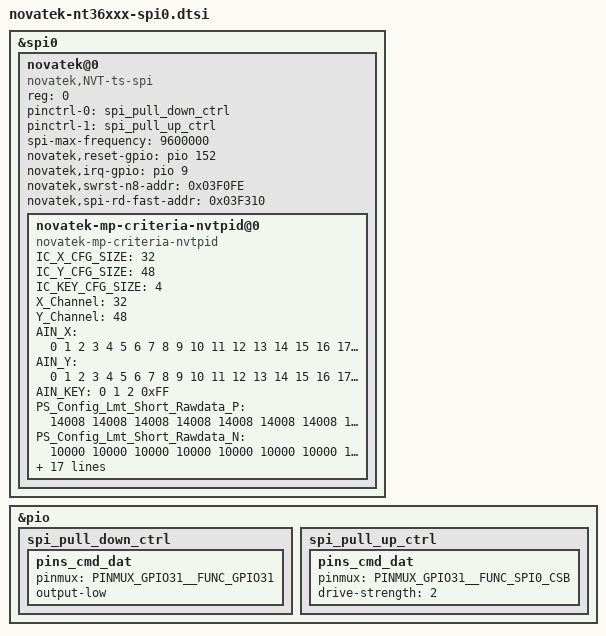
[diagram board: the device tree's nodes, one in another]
// SPDX-License-Identifier: GPL-2.0
/*
 * Copyright (c) 2022 MediaTek Inc.
 *
 */

&spi0 {
	status = "okay";
	#address-cells = <1>;
	#size-cells = <0>;
	/* Novatek device tree node */
	novatek@0 {
		compatible = "novatek,NVT-ts-spi";
		reg = <0>; //Same as CS ID
		status = "okay";
		pinctrl-names = "spi_pull_down", "spi_pull_up";
                pinctrl-0 = <&spi_pull_down_ctrl>;
                pinctrl-1 = <&spi_pull_up_ctrl>;
		//4800000,9600000,15000000,19200000
		spi-max-frequency = <9600000>;
		novatek,reset-gpio = <&pio 152 0x00>;
		novatek,irq-gpio = <&pio 9 0x00>;
		/* 525 */
		//novatek,swrst-n8-addr = <0x01F01A>;
		/* 672A, 525B, 675, 526, 672C, 523 */
		novatek,swrst-n8-addr = <0x03F0FE>;
		novatek,spi-rd-fast-addr = <0x03F310>;
		/* MP */
		//novatek,mp-support-dt;
		
		
		novatek-mp-criteria-nvtpid@0 {
			#address-cells = <1>;
			#size-cells = <0>;
			compatible = "novatek-mp-criteria-nvtpid";

			/* MP Config */
			IC_X_CFG_SIZE = <32>;
			IC_Y_CFG_SIZE = <48>;
			IC_KEY_CFG_SIZE = <4>;
			X_Channel = <32>;
			Y_Channel = <48>;
			AIN_X = <0 1 2 3 4 5 6 7 8 9 10 11 12 13 14 15 16 17 18 19 20 21 22 23 24 25 26 27 28 29 30 31>;
			AIN_Y = <0 1 2 3 4 5 6 7 8 9 10 11 12 13 14 15 16 17 18 19 20 21 22 23 24 25 26 27 28 29 30 31 32 33 34 35 36 37 38 39 40 41 42 43 44 45 46 47>;
			AIN_KEY = <0 1 2 0xFF>;

			/* MP Criteria */
			PS_Config_Lmt_Short_Rawdata_P = <
				14008 14008 14008 14008 14008 14008 14008 14008 14008 14008 14008 14008 14008 14008 14008 14008 14008 14008 14008 14008 14008 14008 14008 14008 14008 14008 14008 14008 14008 14008 14008 14008
				14008 14008 14008 14008 14008 14008 14008 14008 14008 14008 14008 14008 14008 14008 14008 14008 14008 14008 14008 14008 14008 14008 14008 14008 14008 14008 14008 14008 14008 14008 14008 14008
				14008 14008 14008 14008 14008 14008 14008 14008 14008 14008 14008 14008 14008 14008 14008 14008 14008 14008 14008 14008 14008 14008 14008 14008 14008 14008 14008 14008 14008 14008 14008 14008
				14008 14008 14008 14008 14008 14008 14008 14008 14008 14008 14008 14008 14008 14008 14008 14008 14008 14008 14008 14008 14008 14008 14008 14008 14008 14008 14008 14008 14008 14008 14008 14008
				14008 14008 14008 14008 14008 14008 14008 14008 14008 14008 14008 14008 14008 14008 14008 14008 14008 14008 14008 14008 14008 14008 14008 14008 14008 14008 14008 14008 14008 14008 14008 14008
				14008 14008 14008 14008 14008 14008 14008 14008 14008 14008 14008 14008 14008 14008 14008 14008 14008 14008 14008 14008 14008 14008 14008 14008 14008 14008 14008 14008 14008 14008 14008 14008
				14008 14008 14008 14008 14008 14008 14008 14008 14008 14008 14008 14008 14008 14008 14008 14008 14008 14008 14008 14008 14008 14008 14008 14008 14008 14008 14008 14008 14008 14008 14008 14008
				14008 14008 14008 14008 14008 14008 14008 14008 14008 14008 14008 14008 14008 14008 14008 14008 14008 14008 14008 14008 14008 14008 14008 14008 14008 14008 14008 14008 14008 14008 14008 14008
				14008 14008 14008 14008 14008 14008 14008 14008 14008 14008 14008 14008 14008 14008 14008 14008 14008 14008 14008 14008 14008 14008 14008 14008 14008 14008 14008 14008 14008 14008 14008 14008
				14008 14008 14008 14008 14008 14008 14008 14008 14008 14008 14008 14008 14008 14008 14008 14008 14008 14008 14008 14008 14008 14008 14008 14008 14008 14008 14008 14008 14008 14008 14008 14008
				14008 14008 14008 14008 14008 14008 14008 14008 14008 14008 14008 14008 14008 14008 14008 14008 14008 14008 14008 14008 14008 14008 14008 14008 14008 14008 14008 14008 14008 14008 14008 14008
				14008 14008 14008 14008 14008 14008 14008 14008 14008 14008 14008 14008 14008 14008 14008 14008 14008 14008 14008 14008 14008 14008 14008 14008 14008 14008 14008 14008 14008 14008 14008 14008
				14008 14008 14008 14008 14008 14008 14008 14008 14008 14008 14008 14008 14008 14008 14008 14008 14008 14008 14008 14008 14008 14008 14008 14008 14008 14008 14008 14008 14008 14008 14008 14008
				14008 14008 14008 14008 14008 14008 14008 14008 14008 14008 14008 14008 14008 14008 14008 14008 14008 14008 14008 14008 14008 14008 14008 14008 14008 14008 14008 14008 14008 14008 14008 14008
				14008 14008 14008 14008 14008 14008 14008 14008 14008 14008 14008 14008 14008 14008 14008 14008 14008 14008 14008 14008 14008 14008 14008 14008 14008 14008 14008 14008 14008 14008 14008 14008
				14008 14008 14008 14008 14008 14008 14008 14008 14008 14008 14008 14008 14008 14008 14008 14008 14008 14008 14008 14008 14008 14008 14008 14008 14008 14008 14008 14008 14008 14008 14008 14008
				14008 14008 14008 14008 14008 14008 14008 14008 14008 14008 14008 14008 14008 14008 14008 14008 14008 14008 14008 14008 14008 14008 14008 14008 14008 14008 14008 14008 14008 14008 14008 14008
				14008 14008 14008 14008 14008 14008 14008 14008 14008 14008 14008 14008 14008 14008 14008 14008 14008 14008 14008 14008 14008 14008 14008 14008 14008 14008 14008 14008 14008 14008 14008 14008
				14008 14008 14008 14008 14008 14008 14008 14008 14008 14008 14008 14008 14008 14008 14008 14008 14008 14008 14008 14008 14008 14008 14008 14008 14008 14008 14008 14008 14008 14008 14008 14008
				14008 14008 14008 14008 14008 14008 14008 14008 14008 14008 14008 14008 14008 14008 14008 14008 14008 14008 14008 14008 14008 14008 14008 14008 14008 14008 14008 14008 14008 14008 14008 14008
				14008 14008 14008 14008 14008 14008 14008 14008 14008 14008 14008 14008 14008 14008 14008 14008 14008 14008 14008 14008 14008 14008 14008 14008 14008 14008 14008 14008 14008 14008 14008 14008
				14008 14008 14008 14008 14008 14008 14008 14008 14008 14008 14008 14008 14008 14008 14008 14008 14008 14008 14008 14008 14008 14008 14008 14008 14008 14008 14008 14008 14008 14008 14008 14008
				14008 14008 14008 14008 14008 14008 14008 14008 14008 14008 14008 14008 14008 14008 14008 14008 14008 14008 14008 14008 14008 14008 14008 14008 14008 14008 14008 14008 14008 14008 14008 14008
				14008 14008 14008 14008 14008 14008 14008 14008 14008 14008 14008 14008 14008 14008 14008 14008 14008 14008 14008 14008 14008 14008 14008 14008 14008 14008 14008 14008 14008 14008 14008 14008
				14008 14008 14008 14008 14008 14008 14008 14008 14008 14008 14008 14008 14008 14008 14008 14008 14008 14008 14008 14008 14008 14008 14008 14008 14008 14008 14008 14008 14008 14008 14008 14008
				14008 14008 14008 14008 14008 14008 14008 14008 14008 14008 14008 14008 14008 14008 14008 14008 14008 14008 14008 14008 14008 14008 14008 14008 14008 14008 14008 14008 14008 14008 14008 14008
				14008 14008 14008 14008 14008 14008 14008 14008 14008 14008 14008 14008 14008 14008 14008 14008 14008 14008 14008 14008 14008 14008 14008 14008 14008 14008 14008 14008 14008 14008 14008 14008
				14008 14008 14008 14008 14008 14008 14008 14008 14008 14008 14008 14008 14008 14008 14008 14008 14008 14008 14008 14008 14008 14008 14008 14008 14008 14008 14008 14008 14008 14008 14008 14008
				14008 14008 14008 14008 14008 14008 14008 14008 14008 14008 14008 14008 14008 14008 14008 14008 14008 14008 14008 14008 14008 14008 14008 14008 14008 14008 14008 14008 14008 14008 14008 14008
				14008 14008 14008 14008 14008 14008 14008 14008 14008 14008 14008 14008 14008 14008 14008 14008 14008 14008 14008 14008 14008 14008 14008 14008 14008 14008 14008 14008 14008 14008 14008 14008
				14008 14008 14008 14008 14008 14008 14008 14008 14008 14008 14008 14008 14008 14008 14008 14008 14008 14008 14008 14008 14008 14008 14008 14008 14008 14008 14008 14008 14008 14008 14008 14008
				14008 14008 14008 14008 14008 14008 14008 14008 14008 14008 14008 14008 14008 14008 14008 14008 14008 14008 14008 14008 14008 14008 14008 14008 14008 14008 14008 14008 14008 14008 14008 14008
				14008 14008 14008 14008 14008 14008 14008 14008 14008 14008 14008 14008 14008 14008 14008 14008 14008 14008 14008 14008 14008 14008 14008 14008 14008 14008 14008 14008 14008 14008 14008 14008
				14008 14008 14008 14008 14008 14008 14008 14008 14008 14008 14008 14008 14008 14008 14008 14008 14008 14008 14008 14008 14008 14008 14008 14008 14008 14008 14008 14008 14008 14008 14008 14008
				14008 14008 14008 14008 14008 14008 14008 14008 14008 14008 14008 14008 14008 14008 14008 14008 14008 14008 14008 14008 14008 14008 14008 14008 14008 14008 14008 14008 14008 14008 14008 14008
				14008 14008 14008 14008 14008 14008 14008 14008 14008 14008 14008 14008 14008 14008 14008 14008 14008 14008 14008 14008 14008 14008 14008 14008 14008 14008 14008 14008 14008 14008 14008 14008
				14008 14008 14008 14008 14008 14008 14008 14008 14008 14008 14008 14008 14008 14008 14008 14008 14008 14008 14008 14008 14008 14008 14008 14008 14008 14008 14008 14008 14008 14008 14008 14008
				14008 14008 14008 14008 14008 14008 14008 14008 14008 14008 14008 14008 14008 14008 14008 14008 14008 14008 14008 14008 14008 14008 14008 14008 14008 14008 14008 14008 14008 14008 14008 14008
				14008 14008 14008 14008 14008 14008 14008 14008 14008 14008 14008 14008 14008 14008 14008 14008 14008 14008 14008 14008 14008 14008 14008 14008 14008 14008 14008 14008 14008 14008 14008 14008
				14008 14008 14008 14008 14008 14008 14008 14008 14008 14008 14008 14008 14008 14008 14008 14008 14008 14008 14008 14008 14008 14008 14008 14008 14008 14008 14008 14008 14008 14008 14008 14008
				14008 14008 14008 14008 14008 14008 14008 14008 14008 14008 14008 14008 14008 14008 14008 14008 14008 14008 14008 14008 14008 14008 14008 14008 14008 14008 14008 14008 14008 14008 14008 14008
				14008 14008 14008 14008 14008 14008 14008 14008 14008 14008 14008 14008 14008 14008 14008 14008 14008 14008 14008 14008 14008 14008 14008 14008 14008 14008 14008 14008 14008 14008 14008 14008
				14008 14008 14008 14008 14008 14008 14008 14008 14008 14008 14008 14008 14008 14008 14008 14008 14008 14008 14008 14008 14008 14008 14008 14008 14008 14008 14008 14008 14008 14008 14008 14008
				14008 14008 14008 14008 14008 14008 14008 14008 14008 14008 14008 14008 14008 14008 14008 14008 14008 14008 14008 14008 14008 14008 14008 14008 14008 14008 14008 14008 14008 14008 14008 14008
				14008 14008 14008 14008 14008 14008 14008 14008 14008 14008 14008 14008 14008 14008 14008 14008 14008 14008 14008 14008 14008 14008 14008 14008 14008 14008 14008 14008 14008 14008 14008 14008
				14008 14008 14008 14008 14008 14008 14008 14008 14008 14008 14008 14008 14008 14008 14008 14008 14008 14008 14008 14008 14008 14008 14008 14008 14008 14008 14008 14008 14008 14008 14008 14008
				14008 14008 14008 14008 14008 14008 14008 14008 14008 14008 14008 14008 14008 14008 14008 14008 14008 14008 14008 14008 14008 14008 14008 14008 14008 14008 14008 14008 14008 14008 14008 14008
				14008 14008 14008 14008 14008 14008 14008 14008 14008 14008 14008 14008 14008 14008 14008 14008 14008 14008 14008 14008 14008 14008 14008 14008 14008 14008 14008 14008 14008 14008 14008 14008
				14008 14008 14008>;

			PS_Config_Lmt_Short_Rawdata_N = <
				10000 10000 10000 10000 10000 10000 10000 10000 10000 10000 10000 10000 10000 10000 10000 10000 10000 10000 10000 10000 10000 10000 10000 10000 10000 10000 10000 10000 10000 10000 10000 10000
				10000 10000 10000 10000 10000 10000 10000 10000 10000 10000 10000 10000 10000 10000 10000 10000 10000 10000 10000 10000 10000 10000 10000 10000 10000 10000 10000 10000 10000 10000 10000 10000
				10000 10000 10000 10000 10000 10000 10000 10000 10000 10000 10000 10000 10000 10000 10000 10000 10000 10000 10000 10000 10000 10000 10000 10000 10000 10000 10000 10000 10000 10000 10000 10000
				10000 10000 10000 10000 10000 10000 10000 10000 10000 10000 10000 10000 10000 10000 10000 10000 10000 10000 10000 10000 10000 10000 10000 10000 10000 10000 10000 10000 10000 10000 10000 10000
				10000 10000 10000 10000 10000 10000 10000 10000 10000 10000 10000 10000 10000 10000 10000 10000 10000 10000 10000 10000 10000 10000 10000 10000 10000 10000 10000 10000 10000 10000 10000 10000
				10000 10000 10000 10000 10000 10000 10000 10000 10000 10000 10000 10000 10000 10000 10000 10000 10000 10000 10000 10000 10000 10000 10000 10000 10000 10000 10000 10000 10000 10000 10000 10000
				10000 10000 10000 10000 10000 10000 10000 10000 10000 10000 10000 10000 10000 10000 10000 10000 10000 10000 10000 10000 10000 10000 10000 10000 10000 10000 10000 10000 10000 10000 10000 10000
				10000 10000 10000 10000 10000 10000 10000 10000 10000 10000 10000 10000 10000 10000 10000 10000 10000 10000 10000 10000 10000 10000 10000 10000 10000 10000 10000 10000 10000 10000 10000 10000
				10000 10000 10000 10000 10000 10000 10000 10000 10000 10000 10000 10000 10000 10000 10000 10000 10000 10000 10000 10000 10000 10000 10000 10000 10000 10000 10000 10000 10000 10000 10000 10000
				10000 10000 10000 10000 10000 10000 10000 10000 10000 10000 10000 10000 10000 10000 10000 10000 10000 10000 10000 10000 10000 10000 10000 10000 10000 10000 10000 10000 10000 10000 10000 10000
				10000 10000 10000 10000 10000 10000 10000 10000 10000 10000 10000 10000 10000 10000 10000 10000 10000 10000 10000 10000 10000 10000 10000 10000 10000 10000 10000 10000 10000 10000 10000 10000
				10000 10000 10000 10000 10000 10000 10000 10000 10000 10000 10000 10000 10000 10000 10000 10000 10000 10000 10000 10000 10000 10000 10000 10000 10000 10000 10000 10000 10000 10000 10000 10000
				10000 10000 10000 10000 10000 10000 10000 10000 10000 10000 10000 10000 10000 10000 10000 10000 10000 10000 10000 10000 10000 10000 10000 10000 10000 10000 10000 10000 10000 10000 10000 10000
				10000 10000 10000 10000 10000 10000 10000 10000 10000 10000 10000 10000 10000 10000 10000 10000 10000 10000 10000 10000 10000 10000 10000 10000 10000 10000 10000 10000 10000 10000 10000 10000
				10000 10000 10000 10000 10000 10000 10000 10000 10000 10000 10000 10000 10000 10000 10000 10000 10000 10000 10000 10000 10000 10000 10000 10000 10000 10000 10000 10000 10000 10000 10000 10000
				10000 10000 10000 10000 10000 10000 10000 10000 10000 10000 10000 10000 10000 10000 10000 10000 10000 10000 10000 10000 10000 10000 10000 10000 10000 10000 10000 10000 10000 10000 10000 10000
				10000 10000 10000 10000 10000 10000 10000 10000 10000 10000 10000 10000 10000 10000 10000 10000 10000 10000 10000 10000 10000 10000 10000 10000 10000 10000 10000 10000 10000 10000 10000 10000
				10000 10000 10000 10000 10000 10000 10000 10000 10000 10000 10000 10000 10000 10000 10000 10000 10000 10000 10000 10000 10000 10000 10000 10000 10000 10000 10000 10000 10000 10000 10000 10000
				10000 10000 10000 10000 10000 10000 10000 10000 10000 10000 10000 10000 10000 10000 10000 10000 10000 10000 10000 10000 10000 10000 10000 10000 10000 10000 10000 10000 10000 10000 10000 10000
				10000 10000 10000 10000 10000 10000 10000 10000 10000 10000 10000 10000 10000 10000 10000 10000 10000 10000 10000 10000 10000 10000 10000 10000 10000 10000 10000 10000 10000 10000 10000 10000
				10000 10000 10000 10000 10000 10000 10000 10000 10000 10000 10000 10000 10000 10000 10000 10000 10000 10000 10000 10000 10000 10000 10000 10000 10000 10000 10000 10000 10000 10000 10000 10000
				10000 10000 10000 10000 10000 10000 10000 10000 10000 10000 10000 10000 10000 10000 10000 10000 10000 10000 10000 10000 10000 10000 10000 10000 10000 10000 10000 10000 10000 10000 10000 10000
				10000 10000 10000 10000 10000 10000 10000 10000 10000 10000 10000 10000 10000 10000 10000 10000 10000 10000 10000 10000 10000 10000 10000 10000 10000 10000 10000 10000 10000 10000 10000 10000
				10000 10000 10000 10000 10000 10000 10000 10000 10000 10000 10000 10000 10000 10000 10000 10000 10000 10000 10000 10000 10000 10000 10000 10000 10000 10000 10000 10000 10000 10000 10000 10000
				10000 10000 10000 10000 10000 10000 10000 10000 10000 10000 10000 10000 10000 10000 10000 10000 10000 10000 10000 10000 10000 10000 10000 10000 10000 10000 10000 10000 10000 10000 10000 10000
				10000 10000 10000 10000 10000 10000 10000 10000 10000 10000 10000 10000 10000 10000 10000 10000 10000 10000 10000 10000 10000 10000 10000 10000 10000 10000 10000 10000 10000 10000 10000 10000
				10000 10000 10000 10000 10000 10000 10000 10000 10000 10000 10000 10000 10000 10000 10000 10000 10000 10000 10000 10000 10000 10000 10000 10000 10000 10000 10000 10000 10000 10000 10000 10000
				10000 10000 10000 10000 10000 10000 10000 10000 10000 10000 10000 10000 10000 10000 10000 10000 10000 10000 10000 10000 10000 10000 10000 10000 10000 10000 10000 10000 10000 10000 10000 10000
				10000 10000 10000 10000 10000 10000 10000 10000 10000 10000 10000 10000 10000 10000 10000 10000 10000 10000 10000 10000 10000 10000 10000 10000 10000 10000 10000 10000 10000 10000 10000 10000
				10000 10000 10000 10000 10000 10000 10000 10000 10000 10000 10000 10000 10000 10000 10000 10000 10000 10000 10000 10000 10000 10000 10000 10000 10000 10000 10000 10000 10000 10000 10000 10000
				10000 10000 10000 10000 10000 10000 10000 10000 10000 10000 10000 10000 10000 10000 10000 10000 10000 10000 10000 10000 10000 10000 10000 10000 10000 10000 10000 10000 10000 10000 10000 10000
				10000 10000 10000 10000 10000 10000 10000 10000 10000 10000 10000 10000 10000 10000 10000 10000 10000 10000 10000 10000 10000 10000 10000 10000 10000 10000 10000 10000 10000 10000 10000 10000
				10000 10000 10000 10000 10000 10000 10000 10000 10000 10000 10000 10000 10000 10000 10000 10000 10000 10000 10000 10000 10000 10000 10000 10000 10000 10000 10000 10000 10000 10000 10000 10000
				10000 10000 10000 10000 10000 10000 10000 10000 10000 10000 10000 10000 10000 10000 10000 10000 10000 10000 10000 10000 10000 10000 10000 10000 10000 10000 10000 10000 10000 10000 10000 10000
				10000 10000 10000 10000 10000 10000 10000 10000 10000 10000 10000 10000 10000 10000 10000 10000 10000 10000 10000 10000 10000 10000 10000 10000 10000 10000 10000 10000 10000 10000 10000 10000
				10000 10000 10000 10000 10000 10000 10000 10000 10000 10000 10000 10000 10000 10000 10000 10000 10000 10000 10000 10000 10000 10000 10000 10000 10000 10000 10000 10000 10000 10000 10000 10000
				10000 10000 10000 10000 10000 10000 10000 10000 10000 10000 10000 10000 10000 10000 10000 10000 10000 10000 10000 10000 10000 10000 10000 10000 10000 10000 10000 10000 10000 10000 10000 10000
				10000 10000 10000 10000 10000 10000 10000 10000 10000 10000 10000 10000 10000 10000 10000 10000 10000 10000 10000 10000 10000 10000 10000 10000 10000 10000 10000 10000 10000 10000 10000 10000
				10000 10000 10000 10000 10000 10000 10000 10000 10000 10000 10000 10000 10000 10000 10000 10000 10000 10000 10000 10000 10000 10000 10000 10000 10000 10000 10000 10000 10000 10000 10000 10000
				10000 10000 10000 10000 10000 10000 10000 10000 10000 10000 10000 10000 10000 10000 10000 10000 10000 10000 10000 10000 10000 10000 10000 10000 10000 10000 10000 10000 10000 10000 10000 10000
				10000 10000 10000 10000 10000 10000 10000 10000 10000 10000 10000 10000 10000 10000 10000 10000 10000 10000 10000 10000 10000 10000 10000 10000 10000 10000 10000 10000 10000 10000 10000 10000
				10000 10000 10000 10000 10000 10000 10000 10000 10000 10000 10000 10000 10000 10000 10000 10000 10000 10000 10000 10000 10000 10000 10000 10000 10000 10000 10000 10000 10000 10000 10000 10000
				10000 10000 10000 10000 10000 10000 10000 10000 10000 10000 10000 10000 10000 10000 10000 10000 10000 10000 10000 10000 10000 10000 10000 10000 10000 10000 10000 10000 10000 10000 10000 10000
				10000 10000 10000 10000 10000 10000 10000 10000 10000 10000 10000 10000 10000 10000 10000 10000 10000 10000 10000 10000 10000 10000 10000 10000 10000 10000 10000 10000 10000 10000 10000 10000
				10000 10000 10000 10000 10000 10000 10000 10000 10000 10000 10000 10000 10000 10000 10000 10000 10000 10000 10000 10000 10000 10000 10000 10000 10000 10000 10000 10000 10000 10000 10000 10000
				10000 10000 10000 10000 10000 10000 10000 10000 10000 10000 10000 10000 10000 10000 10000 10000 10000 10000 10000 10000 10000 10000 10000 10000 10000 10000 10000 10000 10000 10000 10000 10000
				10000 10000 10000 10000 10000 10000 10000 10000 10000 10000 10000 10000 10000 10000 10000 10000 10000 10000 10000 10000 10000 10000 10000 10000 10000 10000 10000 10000 10000 10000 10000 10000
				10000 10000 10000 10000 10000 10000 10000 10000 10000 10000 10000 10000 10000 10000 10000 10000 10000 10000 10000 10000 10000 10000 10000 10000 10000 10000 10000 10000 10000 10000 10000 10000
				10000 10000 10000>;

			PS_Config_Lmt_Open_Rawdata_P = <
				5120 5120 5120 5120 5120 5120 5120 5120 5120 5120 5120 5120 5120 5120 5120 5120 5120 5120 5120 5120 5120 5120 5120 5120 5120 5120 5120 5120 5120 5120 5120 5120
				5120 5120 5120 5120 5120 5120 5120 5120 5120 5120 5120 5120 5120 5120 5120 5120 5120 5120 5120 5120 5120 5120 5120 5120 5120 5120 5120 5120 5120 5120 5120 5120
				5120 5120 5120 5120 5120 5120 5120 5120 5120 5120 5120 5120 5120 5120 5120 5120 5120 5120 5120 5120 5120 5120 5120 5120 5120 5120 5120 5120 5120 5120 5120 5120
				5120 5120 5120 5120 5120 5120 5120 5120 5120 5120 5120 5120 5120 5120 5120 5120 5120 5120 5120 5120 5120 5120 5120 5120 5120 5120 5120 5120 5120 5120 5120 5120
				5120 5120 5120 5120 5120 5120 5120 5120 5120 5120 5120 5120 5120 5120 5120 5120 5120 5120 5120 5120 5120 5120 5120 5120 5120 5120 5120 5120 5120 5120 5120 5120
				5120 5120 5120 5120 5120 5120 5120 5120 5120 5120 5120 5120 5120 5120 5120 5120 5120 5120 5120 5120 5120 5120 5120 5120 5120 5120 5120 5120 5120 5120 5120 5120
				5120 5120 5120 5120 5120 5120 5120 5120 5120 5120 5120 5120 5120 5120 5120 5120 5120 5120 5120 5120 5120 5120 5120 5120 5120 5120 5120 5120 5120 5120 5120 5120
				5120 5120 5120 5120 5120 5120 5120 5120 5120 5120 5120 5120 5120 5120 5120 5120 5120 5120 5120 5120 5120 5120 5120 5120 5120 5120 5120 5120 5120 5120 5120 5120
				5120 5120 5120 5120 5120 5120 5120 5120 5120 5120 5120 5120 5120 5120 5120 5120 5120 5120 5120 5120 5120 5120 5120 5120 5120 5120 5120 5120 5120 5120 5120 5120
				5120 5120 5120 5120 5120 5120 5120 5120 5120 5120 5120 5120 5120 5120 5120 5120 5120 5120 5120 5120 5120 5120 5120 5120 5120 5120 5120 5120 5120 5120 5120 5120
				5120 5120 5120 5120 5120 5120 5120 5120 5120 5120 5120 5120 5120 5120 5120 5120 5120 5120 5120 5120 5120 5120 5120 5120 5120 5120 5120 5120 5120 5120 5120 5120
				5120 5120 5120 5120 5120 5120 5120 5120 5120 5120 5120 5120 5120 5120 5120 5120 5120 5120 5120 5120 5120 5120 5120 5120 5120 5120 5120 5120 5120 5120 5120 5120
				5120 5120 5120 5120 5120 5120 5120 5120 5120 5120 5120 5120 5120 5120 5120 5120 5120 5120 5120 5120 5120 5120 5120 5120 5120 5120 5120 5120 5120 5120 5120 5120
				5120 5120 5120 5120 5120 5120 5120 5120 5120 5120 5120 5120 5120 5120 5120 5120 5120 5120 5120 5120 5120 5120 5120 5120 5120 5120 5120 5120 5120 5120 5120 5120
				5120 5120 5120 5120 5120 5120 5120 5120 5120 5120 5120 5120 5120 5120 5120 5120 5120 5120 5120 5120 5120 5120 5120 5120 5120 5120 5120 5120 5120 5120 5120 5120
				5120 5120 5120 5120 5120 5120 5120 5120 5120 5120 5120 5120 5120 5120 5120 5120 5120 5120 5120 5120 5120 5120 5120 5120 5120 5120 5120 5120 5120 5120 5120 5120
				5120 5120 5120 5120 5120 5120 5120 5120 5120 5120 5120 5120 5120 5120 5120 5120 5120 5120 5120 5120 5120 5120 5120 5120 5120 5120 5120 5120 5120 5120 5120 5120
				5120 5120 5120 5120 5120 5120 5120 5120 5120 5120 5120 5120 5120 5120 5120 5120 5120 5120 5120 5120 5120 5120 5120 5120 5120 5120 5120 5120 5120 5120 5120 5120
				5120 5120 5120 5120 5120 5120 5120 5120 5120 5120 5120 5120 5120 5120 5120 5120 5120 5120 5120 5120 5120 5120 5120 5120 5120 5120 5120 5120 5120 5120 5120 5120
				5120 5120 5120 5120 5120 5120 5120 5120 5120 5120 5120 5120 5120 5120 5120 5120 5120 5120 5120 5120 5120 5120 5120 5120 5120 5120 5120 5120 5120 5120 5120 5120
				5120 5120 5120 5120 5120 5120 5120 5120 5120 5120 5120 5120 5120 5120 5120 5120 5120 5120 5120 5120 5120 5120 5120 5120 5120 5120 5120 5120 5120 5120 5120 5120
				5120 5120 5120 5120 5120 5120 5120 5120 5120 5120 5120 5120 5120 5120 5120 5120 5120 5120 5120 5120 5120 5120 5120 5120 5120 5120 5120 5120 5120 5120 5120 5120
				5120 5120 5120 5120 5120 5120 5120 5120 5120 5120 5120 5120 5120 5120 5120 5120 5120 5120 5120 5120 5120 5120 5120 5120 5120 5120 5120 5120 5120 5120 5120 5120
				5120 5120 5120 5120 5120 5120 5120 5120 5120 5120 5120 5120 5120 5120 5120 5120 5120 5120 5120 5120 5120 5120 5120 5120 5120 5120 5120 5120 5120 5120 5120 5120
				5120 5120 5120 5120 5120 5120 5120 5120 5120 5120 5120 5120 5120 5120 5120 5120 5120 5120 5120 5120 5120 5120 5120 5120 5120 5120 5120 5120 5120 5120 5120 5120
				5120 5120 5120 5120 5120 5120 5120 5120 5120 5120 5120 5120 5120 5120 5120 5120 5120 5120 5120 5120 5120 5120 5120 5120 5120 5120 5120 5120 5120 5120 5120 5120
				5120 5120 5120 5120 5120 5120 5120 5120 5120 5120 5120 5120 5120 5120 5120 5120 5120 5120 5120 5120 5120 5120 5120 5120 5120 5120 5120 5120 5120 5120 5120 5120
				5120 5120 5120 5120 5120 5120 5120 5120 5120 5120 5120 5120 5120 5120 5120 5120 5120 5120 5120 5120 5120 5120 5120 5120 5120 5120 5120 5120 5120 5120 5120 5120
				5120 5120 5120 5120 5120 5120 5120 5120 5120 5120 5120 5120 5120 5120 5120 5120 5120 5120 5120 5120 5120 5120 5120 5120 5120 5120 5120 5120 5120 5120 5120 5120
				5120 5120 5120 5120 5120 5120 5120 5120 5120 5120 5120 5120 5120 5120 5120 5120 5120 5120 5120 5120 5120 5120 5120 5120 5120 5120 5120 5120 5120 5120 5120 5120
				5120 5120 5120 5120 5120 5120 5120 5120 5120 5120 5120 5120 5120 5120 5120 5120 5120 5120 5120 5120 5120 5120 5120 5120 5120 5120 5120 5120 5120 5120 5120 5120
				5120 5120 5120 5120 5120 5120 5120 5120 5120 5120 5120 5120 5120 5120 5120 5120 5120 5120 5120 5120 5120 5120 5120 5120 5120 5120 5120 5120 5120 5120 5120 5120
				5120 5120 5120 5120 5120 5120 5120 5120 5120 5120 5120 5120 5120 5120 5120 5120 5120 5120 5120 5120 5120 5120 5120 5120 5120 5120 5120 5120 5120 5120 5120 5120
				5120 5120 5120 5120 5120 5120 5120 5120 5120 5120 5120 5120 5120 5120 5120 5120 5120 5120 5120 5120 5120 5120 5120 5120 5120 5120 5120 5120 5120 5120 5120 5120
				5120 5120 5120 5120 5120 5120 5120 5120 5120 5120 5120 5120 5120 5120 5120 5120 5120 5120 5120 5120 5120 5120 5120 5120 5120 5120 5120 5120 5120 5120 5120 5120
				5120 5120 5120 5120 5120 5120 5120 5120 5120 5120 5120 5120 5120 5120 5120 5120 5120 5120 5120 5120 5120 5120 5120 5120 5120 5120 5120 5120 5120 5120 5120 5120
				5120 5120 5120 5120 5120 5120 5120 5120 5120 5120 5120 5120 5120 5120 5120 5120 5120 5120 5120 5120 5120 5120 5120 5120 5120 5120 5120 5120 5120 5120 5120 5120
				5120 5120 5120 5120 5120 5120 5120 5120 5120 5120 5120 5120 5120 5120 5120 5120 5120 5120 5120 5120 5120 5120 5120 5120 5120 5120 5120 5120 5120 5120 5120 5120
				5120 5120 5120 5120 5120 5120 5120 5120 5120 5120 5120 5120 5120 5120 5120 5120 5120 5120 5120 5120 5120 5120 5120 5120 5120 5120 5120 5120 5120 5120 5120 5120
				5120 5120 5120 5120 5120 5120 5120 5120 5120 5120 5120 5120 5120 5120 5120 5120 5120 5120 5120 5120 5120 5120 5120 5120 5120 5120 5120 5120 5120 5120 5120 5120
				5120 5120 5120 5120 5120 5120 5120 5120 5120 5120 5120 5120 5120 5120 5120 5120 5120 5120 5120 5120 5120 5120 5120 5120 5120 5120 5120 5120 5120 5120 5120 5120
				5120 5120 5120 5120 5120 5120 5120 5120 5120 5120 5120 5120 5120 5120 5120 5120 5120 5120 5120 5120 5120 5120 5120 5120 5120 5120 5120 5120 5120 5120 5120 5120
				5120 5120 5120 5120 5120 5120 5120 5120 5120 5120 5120 5120 5120 5120 5120 5120 5120 5120 5120 5120 5120 5120 5120 5120 5120 5120 5120 5120 5120 5120 5120 5120
				5120 5120 5120 5120 5120 5120 5120 5120 5120 5120 5120 5120 5120 5120 5120 5120 5120 5120 5120 5120 5120 5120 5120 5120 5120 5120 5120 5120 5120 5120 5120 5120
				5120 5120 5120 5120 5120 5120 5120 5120 5120 5120 5120 5120 5120 5120 5120 5120 5120 5120 5120 5120 5120 5120 5120 5120 5120 5120 5120 5120 5120 5120 5120 5120
				5120 5120 5120 5120 5120 5120 5120 5120 5120 5120 5120 5120 5120 5120 5120 5120 5120 5120 5120 5120 5120 5120 5120 5120 5120 5120 5120 5120 5120 5120 5120 5120
				5120 5120 5120 5120 5120 5120 5120 5120 5120 5120 5120 5120 5120 5120 5120 5120 5120 5120 5120 5120 5120 5120 5120 5120 5120 5120 5120 5120 5120 5120 5120 5120
				5120 5120 5120 5120 5120 5120 5120 5120 5120 5120 5120 5120 5120 5120 5120 5120 5120 5120 5120 5120 5120 5120 5120 5120 5120 5120 5120 5120 5120 5120 5120 5120
				5120 5120 5120>;

			PS_Config_Lmt_Open_Rawdata_N = <
				(-511) (-511) (-511) (-511) (-511) (-511) (-511) (-511) (-511) (-511) (-511) (-511) (-511) (-511) (-511) (-511) (-511) (-511) (-511) (-511) (-511) (-511) (-511) (-511) (-511) (-511) (-511) (-511) (-511) (-511) (-511) (-511)
				(-511) (-511) (-511) (-511) (-511) (-511) (-511) (-511) (-511) (-511) (-511) (-511) (-511) (-511) (-511) (-511) (-511) (-511) (-511) (-511) (-511) (-511) (-511) (-511) (-511) (-511) (-511) (-511) (-511) (-511) (-511) (-511)
				(-511) (-511) (-511) (-511) (-511) (-511) (-511) (-511) (-511) (-511) (-511) (-511) (-511) (-511) (-511) (-511) (-511) (-511) (-511) (-511) (-511) (-511) (-511) (-511) (-511) (-511) (-511) (-511) (-511) (-511) (-511) (-511)
				(-511) (-511) (-511) (-511) (-511) (-511) (-511) (-511) (-511) (-511) (-511) (-511) (-511) (-511) (-511) (-511) (-511) (-511) (-511) (-511) (-511) (-511) (-511) (-511) (-511) (-511) (-511) (-511) (-511) (-511) (-511) (-511)
				(-511) (-511) (-511) (-511) (-511) (-511) (-511) (-511) (-511) (-511) (-511) (-511) (-511) (-511) (-511) (-511) (-511) (-511) (-511) (-511) (-511) (-511) (-511) (-511) (-511) (-511) (-511) (-511) (-511) (-511) (-511) (-511)
				(-511) (-511) (-511) (-511) (-511) (-511) (-511) (-511) (-511) (-511) (-511) (-511) (-511) (-511) (-511) (-511) (-511) (-511) (-511) (-511) (-511) (-511) (-511) (-511) (-511) (-511) (-511) (-511) (-511) (-511) (-511) (-511)
				(-511) (-511) (-511) (-511) (-511) (-511) (-511) (-511) (-511) (-511) (-511) (-511) (-511) (-511) (-511) (-511) (-511) (-511) (-511) (-511) (-511) (-511) (-511) (-511) (-511) (-511) (-511) (-511) (-511) (-511) (-511) (-511)
				(-511) (-511) (-511) (-511) (-511) (-511) (-511) (-511) (-511) (-511) (-511) (-511) (-511) (-511) (-511) (-511) (-511) (-511) (-511) (-511) (-511) (-511) (-511) (-511) (-511) (-511) (-511) (-511) (-511) (-511) (-511) (-511)
				(-511) (-511) (-511) (-511) (-511) (-511) (-511) (-511) (-511) (-511) (-511) (-511) (-511) (-511) (-511) (-511) (-511) (-511) (-511) (-511) (-511) (-511) (-511) (-511) (-511) (-511) (-511) (-511) (-511) (-511) (-511) (-511)
				(-511) (-511) (-511) (-511) (-511) (-511) (-511) (-511) (-511) (-511) (-511) (-511) (-511) (-511) (-511) (-511) (-511) (-511) (-511) (-511) (-511) (-511) (-511) (-511) (-511) (-511) (-511) (-511) (-511) (-511) (-511) (-511)
				(-511) (-511) (-511) (-511) (-511) (-511) (-511) (-511) (-511) (-511) (-511) (-511) (-511) (-511) (-511) (-511) (-511) (-511) (-511) (-511) (-511) (-511) (-511) (-511) (-511) (-511) (-511) (-511) (-511) (-511) (-511) (-511)
				(-511) (-511) (-511) (-511) (-511) (-511) (-511) (-511) (-511) (-511) (-511) (-511) (-511) (-511) (-511) (-511) (-511) (-511) (-511) (-511) (-511) (-511) (-511) (-511) (-511) (-511) (-511) (-511) (-511) (-511) (-511) (-511)
				(-511) (-511) (-511) (-511) (-511) (-511) (-511) (-511) (-511) (-511) (-511) (-511) (-511) (-511) (-511) (-511) (-511) (-511) (-511) (-511) (-511) (-511) (-511) (-511) (-511) (-511) (-511) (-511) (-511) (-511) (-511) (-511)
				(-511) (-511) (-511) (-511) (-511) (-511) (-511) (-511) (-511) (-511) (-511) (-511) (-511) (-511) (-511) (-511) (-511) (-511) (-511) (-511) (-511) (-511) (-511) (-511) (-511) (-511) (-511) (-511) (-511) (-511) (-511) (-511)
				(-511) (-511) (-511) (-511) (-511) (-511) (-511) (-511) (-511) (-511) (-511) (-511) (-511) (-511) (-511) (-511) (-511) (-511) (-511) (-511) (-511) (-511) (-511) (-511) (-511) (-511) (-511) (-511) (-511) (-511) (-511) (-511)
				(-511) (-511) (-511) (-511) (-511) (-511) (-511) (-511) (-511) (-511) (-511) (-511) (-511) (-511) (-511) (-511) (-511) (-511) (-511) (-511) (-511) (-511) (-511) (-511) (-511) (-511) (-511) (-511) (-511) (-511) (-511) (-511)
				(-511) (-511) (-511) (-511) (-511) (-511) (-511) (-511) (-511) (-511) (-511) (-511) (-511) (-511) (-511) (-511) (-511) (-511) (-511) (-511) (-511) (-511) (-511) (-511) (-511) (-511) (-511) (-511) (-511) (-511) (-511) (-511)
				(-511) (-511) (-511) (-511) (-511) (-511) (-511) (-511) (-511) (-511) (-511) (-511) (-511) (-511) (-511) (-511) (-511) (-511) (-511) (-511) (-511) (-511) (-511) (-511) (-511) (-511) (-511) (-511) (-511) (-511) (-511) (-511)
				(-511) (-511) (-511) (-511) (-511) (-511) (-511) (-511) (-511) (-511) (-511) (-511) (-511) (-511) (-511) (-511) (-511) (-511) (-511) (-511) (-511) (-511) (-511) (-511) (-511) (-511) (-511) (-511) (-511) (-511) (-511) (-511)
				(-511) (-511) (-511) (-511) (-511) (-511) (-511) (-511) (-511) (-511) (-511) (-511) (-511) (-511) (-511) (-511) (-511) (-511) (-511) (-511) (-511) (-511) (-511) (-511) (-511) (-511) (-511) (-511) (-511) (-511) (-511) (-511)
				(-511) (-511) (-511) (-511) (-511) (-511) (-511) (-511) (-511) (-511) (-511) (-511) (-511) (-511) (-511) (-511) (-511) (-511) (-511) (-511) (-511) (-511) (-511) (-511) (-511) (-511) (-511) (-511) (-511) (-511) (-511) (-511)
				(-511) (-511) (-511) (-511) (-511) (-511) (-511) (-511) (-511) (-511) (-511) (-511) (-511) (-511) (-511) (-511) (-511) (-511) (-511) (-511) (-511) (-511) (-511) (-511) (-511) (-511) (-511) (-511) (-511) (-511) (-511) (-511)
				(-511) (-511) (-511) (-511) (-511) (-511) (-511) (-511) (-511) (-511) (-511) (-511) (-511) (-511) (-511) (-511) (-511) (-511) (-511) (-511) (-511) (-511) (-511) (-511) (-511) (-511) (-511) (-511) (-511) (-511) (-511) (-511)
				(-511) (-511) (-511) (-511) (-511) (-511) (-511) (-511) (-511) (-511) (-511) (-511) (-511) (-511) (-511) (-511) (-511) (-511) (-511) (-511) (-511) (-511) (-511) (-511) (-511) (-511) (-511) (-511) (-511) (-511) (-511) (-511)
				(-511) (-511) (-511) (-511) (-511) (-511) (-511) (-511) (-511) (-511) (-511) (-511) (-511) (-511) (-511) (-511) (-511) (-511) (-511) (-511) (-511) (-511) (-511) (-511) (-511) (-511) (-511) (-511) (-511) (-511) (-511) (-511)
				(-511) (-511) (-511) (-511) (-511) (-511) (-511) (-511) (-511) (-511) (-511) (-511) (-511) (-511) (-511) (-511) (-511) (-511) (-511) (-511) (-511) (-511) (-511) (-511) (-511) (-511) (-511) (-511) (-511) (-511) (-511) (-511)
				(-511) (-511) (-511) (-511) (-511) (-511) (-511) (-511) (-511) (-511) (-511) (-511) (-511) (-511) (-511) (-511) (-511) (-511) (-511) (-511) (-511) (-511) (-511) (-511) (-511) (-511) (-511) (-511) (-511) (-511) (-511) (-511)
				(-511) (-511) (-511) (-511) (-511) (-511) (-511) (-511) (-511) (-511) (-511) (-511) (-511) (-511) (-511) (-511) (-511) (-511) (-511) (-511) (-511) (-511) (-511) (-511) (-511) (-511) (-511) (-511) (-511) (-511) (-511) (-511)
				(-511) (-511) (-511) (-511) (-511) (-511) (-511) (-511) (-511) (-511) (-511) (-511) (-511) (-511) (-511) (-511) (-511) (-511) (-511) (-511) (-511) (-511) (-511) (-511) (-511) (-511) (-511) (-511) (-511) (-511) (-511) (-511)
				(-511) (-511) (-511) (-511) (-511) (-511) (-511) (-511) (-511) (-511) (-511) (-511) (-511) (-511) (-511) (-511) (-511) (-511) (-511) (-511) (-511) (-511) (-511) (-511) (-511) (-511) (-511) (-511) (-511) (-511) (-511) (-511)
				(-511) (-511) (-511) (-511) (-511) (-511) (-511) (-511) (-511) (-511) (-511) (-511) (-511) (-511) (-511) (-511) (-511) (-511) (-511) (-511) (-511) (-511) (-511) (-511) (-511) (-511) (-511) (-511) (-511) (-511) (-511) (-511)
				(-511) (-511) (-511) (-511) (-511) (-511) (-511) (-511) (-511) (-511) (-511) (-511) (-511) (-511) (-511) (-511) (-511) (-511) (-511) (-511) (-511) (-511) (-511) (-511) (-511) (-511) (-511) (-511) (-511) (-511) (-511) (-511)
				(-511) (-511) (-511) (-511) (-511) (-511) (-511) (-511) (-511) (-511) (-511) (-511) (-511) (-511) (-511) (-511) (-511) (-511) (-511) (-511) (-511) (-511) (-511) (-511) (-511) (-511) (-511) (-511) (-511) (-511) (-511) (-511)
				(-511) (-511) (-511) (-511) (-511) (-511) (-511) (-511) (-511) (-511) (-511) (-511) (-511) (-511) (-511) (-511) (-511) (-511) (-511) (-511) (-511) (-511) (-511) (-511) (-511) (-511) (-511) (-511) (-511) (-511) (-511) (-511)
				(-511) (-511) (-511) (-511) (-511) (-511) (-511) (-511) (-511) (-511) (-511) (-511) (-511) (-511) (-511) (-511) (-511) (-511) (-511) (-511) (-511) (-511) (-511) (-511) (-511) (-511) (-511) (-511) (-511) (-511) (-511) (-511)
				(-511) (-511) (-511) (-511) (-511) (-511) (-511) (-511) (-511) (-511) (-511) (-511) (-511) (-511) (-511) (-511) (-511) (-511) (-511) (-511) (-511) (-511) (-511) (-511) (-511) (-511) (-511) (-511) (-511) (-511) (-511) (-511)
				(-511) (-511) (-511) (-511) (-511) (-511) (-511) (-511) (-511) (-511) (-511) (-511) (-511) (-511) (-511) (-511) (-511) (-511) (-511) (-511) (-511) (-511) (-511) (-511) (-511) (-511) (-511) (-511) (-511) (-511) (-511) (-511)
				(-511) (-511) (-511) (-511) (-511) (-511) (-511) (-511) (-511) (-511) (-511) (-511) (-511) (-511) (-511) (-511) (-511) (-511) (-511) (-511) (-511) (-511) (-511) (-511) (-511) (-511) (-511) (-511) (-511) (-511) (-511) (-511)
				(-511) (-511) (-511) (-511) (-511) (-511) (-511) (-511) (-511) (-511) (-511) (-511) (-511) (-511) (-511) (-511) (-511) (-511) (-511) (-511) (-511) (-511) (-511) (-511) (-511) (-511) (-511) (-511) (-511) (-511) (-511) (-511)
				(-511) (-511) (-511) (-511) (-511) (-511) (-511) (-511) (-511) (-511) (-511) (-511) (-511) (-511) (-511) (-511) (-511) (-511) (-511) (-511) (-511) (-511) (-511) (-511) (-511) (-511) (-511) (-511) (-511) (-511) (-511) (-511)
				(-511) (-511) (-511) (-511) (-511) (-511) (-511) (-511) (-511) (-511) (-511) (-511) (-511) (-511) (-511) (-511) (-511) (-511) (-511) (-511) (-511) (-511) (-511) (-511) (-511) (-511) (-511) (-511) (-511) (-511) (-511) (-511)
				(-511) (-511) (-511) (-511) (-511) (-511) (-511) (-511) (-511) (-511) (-511) (-511) (-511) (-511) (-511) (-511) (-511) (-511) (-511) (-511) (-511) (-511) (-511) (-511) (-511) (-511) (-511) (-511) (-511) (-511) (-511) (-511)
				(-511) (-511) (-511) (-511) (-511) (-511) (-511) (-511) (-511) (-511) (-511) (-511) (-511) (-511) (-511) (-511) (-511) (-511) (-511) (-511) (-511) (-511) (-511) (-511) (-511) (-511) (-511) (-511) (-511) (-511) (-511) (-511)
				(-511) (-511) (-511) (-511) (-511) (-511) (-511) (-511) (-511) (-511) (-511) (-511) (-511) (-511) (-511) (-511) (-511) (-511) (-511) (-511) (-511) (-511) (-511) (-511) (-511) (-511) (-511) (-511) (-511) (-511) (-511) (-511)
				(-511) (-511) (-511) (-511) (-511) (-511) (-511) (-511) (-511) (-511) (-511) (-511) (-511) (-511) (-511) (-511) (-511) (-511) (-511) (-511) (-511) (-511) (-511) (-511) (-511) (-511) (-511) (-511) (-511) (-511) (-511) (-511)
				(-511) (-511) (-511) (-511) (-511) (-511) (-511) (-511) (-511) (-511) (-511) (-511) (-511) (-511) (-511) (-511) (-511) (-511) (-511) (-511) (-511) (-511) (-511) (-511) (-511) (-511) (-511) (-511) (-511) (-511) (-511) (-511)
				(-511) (-511) (-511) (-511) (-511) (-511) (-511) (-511) (-511) (-511) (-511) (-511) (-511) (-511) (-511) (-511) (-511) (-511) (-511) (-511) (-511) (-511) (-511) (-511) (-511) (-511) (-511) (-511) (-511) (-511) (-511) (-511)
				(-511) (-511) (-511) (-511) (-511) (-511) (-511) (-511) (-511) (-511) (-511) (-511) (-511) (-511) (-511) (-511) (-511) (-511) (-511) (-511) (-511) (-511) (-511) (-511) (-511) (-511) (-511) (-511) (-511) (-511) (-511) (-511)
				(-511) (-511) (-511)>;

			PS_Config_Lmt_FW_Rawdata_P = <
				3840 3840 3840 3840 3840 3840 3840 3840 3840 3840 3840 3840 3840 3840 3840 3840 3840 3840 3840 3840 3840 3840 3840 3840 3840 3840 3840 3840 3840 3840 3840 3840
				3840 3840 3840 3840 3840 3840 3840 3840 3840 3840 3840 3840 3840 3840 3840 3840 3840 3840 3840 3840 3840 3840 3840 3840 3840 3840 3840 3840 3840 3840 3840 3840
				3840 3840 3840 3840 3840 3840 3840 3840 3840 3840 3840 3840 3840 3840 3840 3840 3840 3840 3840 3840 3840 3840 3840 3840 3840 3840 3840 3840 3840 3840 3840 3840
				3840 3840 3840 3840 3840 3840 3840 3840 3840 3840 3840 3840 3840 3840 3840 3840 3840 3840 3840 3840 3840 3840 3840 3840 3840 3840 3840 3840 3840 3840 3840 3840
				3840 3840 3840 3840 3840 3840 3840 3840 3840 3840 3840 3840 3840 3840 3840 3840 3840 3840 3840 3840 3840 3840 3840 3840 3840 3840 3840 3840 3840 3840 3840 3840
				3840 3840 3840 3840 3840 3840 3840 3840 3840 3840 3840 3840 3840 3840 3840 3840 3840 3840 3840 3840 3840 3840 3840 3840 3840 3840 3840 3840 3840 3840 3840 3840
				3840 3840 3840 3840 3840 3840 3840 3840 3840 3840 3840 3840 3840 3840 3840 3840 3840 3840 3840 3840 3840 3840 3840 3840 3840 3840 3840 3840 3840 3840 3840 3840
				3840 3840 3840 3840 3840 3840 3840 3840 3840 3840 3840 3840 3840 3840 3840 3840 3840 3840 3840 3840 3840 3840 3840 3840 3840 3840 3840 3840 3840 3840 3840 3840
				3840 3840 3840 3840 3840 3840 3840 3840 3840 3840 3840 3840 3840 3840 3840 3840 3840 3840 3840 3840 3840 3840 3840 3840 3840 3840 3840 3840 3840 3840 3840 3840
				3840 3840 3840 3840 3840 3840 3840 3840 3840 3840 3840 3840 3840 3840 3840 3840 3840 3840 3840 3840 3840 3840 3840 3840 3840 3840 3840 3840 3840 3840 3840 3840
				3840 3840 3840 3840 3840 3840 3840 3840 3840 3840 3840 3840 3840 3840 3840 3840 3840 3840 3840 3840 3840 3840 3840 3840 3840 3840 3840 3840 3840 3840 3840 3840
				3840 3840 3840 3840 3840 3840 3840 3840 3840 3840 3840 3840 3840 3840 3840 3840 3840 3840 3840 3840 3840 3840 3840 3840 3840 3840 3840 3840 3840 3840 3840 3840
				3840 3840 3840 3840 3840 3840 3840 3840 3840 3840 3840 3840 3840 3840 3840 3840 3840 3840 3840 3840 3840 3840 3840 3840 3840 3840 3840 3840 3840 3840 3840 3840
				3840 3840 3840 3840 3840 3840 3840 3840 3840 3840 3840 3840 3840 3840 3840 3840 3840 3840 3840 3840 3840 3840 3840 3840 3840 3840 3840 3840 3840 3840 3840 3840
				3840 3840 3840 3840 3840 3840 3840 3840 3840 3840 3840 3840 3840 3840 3840 3840 3840 3840 3840 3840 3840 3840 3840 3840 3840 3840 3840 3840 3840 3840 3840 3840
				3840 3840 3840 3840 3840 3840 3840 3840 3840 3840 3840 3840 3840 3840 3840 3840 3840 3840 3840 3840 3840 3840 3840 3840 3840 3840 3840 3840 3840 3840 3840 3840
				3840 3840 3840 3840 3840 3840 3840 3840 3840 3840 3840 3840 3840 3840 3840 3840 3840 3840 3840 3840 3840 3840 3840 3840 3840 3840 3840 3840 3840 3840 3840 3840
				3840 3840 3840 3840 3840 3840 3840 3840 3840 3840 3840 3840 3840 3840 3840 3840 3840 3840 3840 3840 3840 3840 3840 3840 3840 3840 3840 3840 3840 3840 3840 3840
				3840 3840 3840 3840 3840 3840 3840 3840 3840 3840 3840 3840 3840 3840 3840 3840 3840 3840 3840 3840 3840 3840 3840 3840 3840 3840 3840 3840 3840 3840 3840 3840
				3840 3840 3840 3840 3840 3840 3840 3840 3840 3840 3840 3840 3840 3840 3840 3840 3840 3840 3840 3840 3840 3840 3840 3840 3840 3840 3840 3840 3840 3840 3840 3840
				3840 3840 3840 3840 3840 3840 3840 3840 3840 3840 3840 3840 3840 3840 3840 3840 3840 3840 3840 3840 3840 3840 3840 3840 3840 3840 3840 3840 3840 3840 3840 3840
				3840 3840 3840 3840 3840 3840 3840 3840 3840 3840 3840 3840 3840 3840 3840 3840 3840 3840 3840 3840 3840 3840 3840 3840 3840 3840 3840 3840 3840 3840 3840 3840
				3840 3840 3840 3840 3840 3840 3840 3840 3840 3840 3840 3840 3840 3840 3840 3840 3840 3840 3840 3840 3840 3840 3840 3840 3840 3840 3840 3840 3840 3840 3840 3840
				3840 3840 3840 3840 3840 3840 3840 3840 3840 3840 3840 3840 3840 3840 3840 3840 3840 3840 3840 3840 3840 3840 3840 3840 3840 3840 3840 3840 3840 3840 3840 3840
				3840 3840 3840 3840 3840 3840 3840 3840 3840 3840 3840 3840 3840 3840 3840 3840 3840 3840 3840 3840 3840 3840 3840 3840 3840 3840 3840 3840 3840 3840 3840 3840
				3840 3840 3840 3840 3840 3840 3840 3840 3840 3840 3840 3840 3840 3840 3840 3840 3840 3840 3840 3840 3840 3840 3840 3840 3840 3840 3840 3840 3840 3840 3840 3840
				3840 3840 3840 3840 3840 3840 3840 3840 3840 3840 3840 3840 3840 3840 3840 3840 3840 3840 3840 3840 3840 3840 3840 3840 3840 3840 3840 3840 3840 3840 3840 3840
				3840 3840 3840 3840 3840 3840 3840 3840 3840 3840 3840 3840 3840 3840 3840 3840 3840 3840 3840 3840 3840 3840 3840 3840 3840 3840 3840 3840 3840 3840 3840 3840
				3840 3840 3840 3840 3840 3840 3840 3840 3840 3840 3840 3840 3840 3840 3840 3840 3840 3840 3840 3840 3840 3840 3840 3840 3840 3840 3840 3840 3840 3840 3840 3840
				3840 3840 3840 3840 3840 3840 3840 3840 3840 3840 3840 3840 3840 3840 3840 3840 3840 3840 3840 3840 3840 3840 3840 3840 3840 3840 3840 3840 3840 3840 3840 3840
				3840 3840 3840 3840 3840 3840 3840 3840 3840 3840 3840 3840 3840 3840 3840 3840 3840 3840 3840 3840 3840 3840 3840 3840 3840 3840 3840 3840 3840 3840 3840 3840
				3840 3840 3840 3840 3840 3840 3840 3840 3840 3840 3840 3840 3840 3840 3840 3840 3840 3840 3840 3840 3840 3840 3840 3840 3840 3840 3840 3840 3840 3840 3840 3840
				3840 3840 3840 3840 3840 3840 3840 3840 3840 3840 3840 3840 3840 3840 3840 3840 3840 3840 3840 3840 3840 3840 3840 3840 3840 3840 3840 3840 3840 3840 3840 3840
				3840 3840 3840 3840 3840 3840 3840 3840 3840 3840 3840 3840 3840 3840 3840 3840 3840 3840 3840 3840 3840 3840 3840 3840 3840 3840 3840 3840 3840 3840 3840 3840
				3840 3840 3840 3840 3840 3840 3840 3840 3840 3840 3840 3840 3840 3840 3840 3840 3840 3840 3840 3840 3840 3840 3840 3840 3840 3840 3840 3840 3840 3840 3840 3840
				3840 3840 3840 3840 3840 3840 3840 3840 3840 3840 3840 3840 3840 3840 3840 3840 3840 3840 3840 3840 3840 3840 3840 3840 3840 3840 3840 3840 3840 3840 3840 3840
				3840 3840 3840 3840 3840 3840 3840 3840 3840 3840 3840 3840 3840 3840 3840 3840 3840 3840 3840 3840 3840 3840 3840 3840 3840 3840 3840 3840 3840 3840 3840 3840
				3840 3840 3840 3840 3840 3840 3840 3840 3840 3840 3840 3840 3840 3840 3840 3840 3840 3840 3840 3840 3840 3840 3840 3840 3840 3840 3840 3840 3840 3840 3840 3840
				3840 3840 3840 3840 3840 3840 3840 3840 3840 3840 3840 3840 3840 3840 3840 3840 3840 3840 3840 3840 3840 3840 3840 3840 3840 3840 3840 3840 3840 3840 3840 3840
				3840 3840 3840 3840 3840 3840 3840 3840 3840 3840 3840 3840 3840 3840 3840 3840 3840 3840 3840 3840 3840 3840 3840 3840 3840 3840 3840 3840 3840 3840 3840 3840
				3840 3840 3840 3840 3840 3840 3840 3840 3840 3840 3840 3840 3840 3840 3840 3840 3840 3840 3840 3840 3840 3840 3840 3840 3840 3840 3840 3840 3840 3840 3840 3840
				3840 3840 3840 3840 3840 3840 3840 3840 3840 3840 3840 3840 3840 3840 3840 3840 3840 3840 3840 3840 3840 3840 3840 3840 3840 3840 3840 3840 3840 3840 3840 3840
				3840 3840 3840 3840 3840 3840 3840 3840 3840 3840 3840 3840 3840 3840 3840 3840 3840 3840 3840 3840 3840 3840 3840 3840 3840 3840 3840 3840 3840 3840 3840 3840
				3840 3840 3840 3840 3840 3840 3840 3840 3840 3840 3840 3840 3840 3840 3840 3840 3840 3840 3840 3840 3840 3840 3840 3840 3840 3840 3840 3840 3840 3840 3840 3840
				3840 3840 3840 3840 3840 3840 3840 3840 3840 3840 3840 3840 3840 3840 3840 3840 3840 3840 3840 3840 3840 3840 3840 3840 3840 3840 3840 3840 3840 3840 3840 3840
				3840 3840 3840 3840 3840 3840 3840 3840 3840 3840 3840 3840 3840 3840 3840 3840 3840 3840 3840 3840 3840 3840 3840 3840 3840 3840 3840 3840 3840 3840 3840 3840
				3840 3840 3840 3840 3840 3840 3840 3840 3840 3840 3840 3840 3840 3840 3840 3840 3840 3840 3840 3840 3840 3840 3840 3840 3840 3840 3840 3840 3840 3840 3840 3840
				3840 3840 3840 3840 3840 3840 3840 3840 3840 3840 3840 3840 3840 3840 3840 3840 3840 3840 3840 3840 3840 3840 3840 3840 3840 3840 3840 3840 3840 3840 3840 3840
				3840 3840 3840>;

			PS_Config_Lmt_FW_Rawdata_N = <
				240 240 240 240 240 240 240 240 240 240 240 240 240 240 240 240 240 240 240 240 240 240 240 240 240 240 240 240 240 240 240 240
				240 240 240 240 240 240 240 240 240 240 240 240 240 240 240 240 240 240 240 240 240 240 240 240 240 240 240 240 240 240 240 240
				240 240 240 240 240 240 240 240 240 240 240 240 240 240 240 240 240 240 240 240 240 240 240 240 240 240 240 240 240 240 240 240
				240 240 240 240 240 240 240 240 240 240 240 240 240 240 240 240 240 240 240 240 240 240 240 240 240 240 240 240 240 240 240 240
				240 240 240 240 240 240 240 240 240 240 240 240 240 240 240 240 240 240 240 240 240 240 240 240 240 240 240 240 240 240 240 240
				240 240 240 240 240 240 240 240 240 240 240 240 240 240 240 240 240 240 240 240 240 240 240 240 240 240 240 240 240 240 240 240
				240 240 240 240 240 240 240 240 240 240 240 240 240 240 240 240 240 240 240 240 240 240 240 240 240 240 240 240 240 240 240 240
				240 240 240 240 240 240 240 240 240 240 240 240 240 240 240 240 240 240 240 240 240 240 240 240 240 240 240 240 240 240 240 240
				240 240 240 240 240 240 240 240 240 240 240 240 240 240 240 240 240 240 240 240 240 240 240 240 240 240 240 240 240 240 240 240
				240 240 240 240 240 240 240 240 240 240 240 240 240 240 240 240 240 240 240 240 240 240 240 240 240 240 240 240 240 240 240 240
				240 240 240 240 240 240 240 240 240 240 240 240 240 240 240 240 240 240 240 240 240 240 240 240 240 240 240 240 240 240 240 240
				240 240 240 240 240 240 240 240 240 240 240 240 240 240 240 240 240 240 240 240 240 240 240 240 240 240 240 240 240 240 240 240
				240 240 240 240 240 240 240 240 240 240 240 240 240 240 240 240 240 240 240 240 240 240 240 240 240 240 240 240 240 240 240 240
				240 240 240 240 240 240 240 240 240 240 240 240 240 240 240 240 240 240 240 240 240 240 240 240 240 240 240 240 240 240 240 240
				240 240 240 240 240 240 240 240 240 240 240 240 240 240 240 240 240 240 240 240 240 240 240 240 240 240 240 240 240 240 240 240
				240 240 240 240 240 240 240 240 240 240 240 240 240 240 240 240 240 240 240 240 240 240 240 240 240 240 240 240 240 240 240 240
				240 240 240 240 240 240 240 240 240 240 240 240 240 240 240 240 240 240 240 240 240 240 240 240 240 240 240 240 240 240 240 240
				240 240 240 240 240 240 240 240 240 240 240 240 240 240 240 240 240 240 240 240 240 240 240 240 240 240 240 240 240 240 240 240
				240 240 240 240 240 240 240 240 240 240 240 240 240 240 240 240 240 240 240 240 240 240 240 240 240 240 240 240 240 240 240 240
				240 240 240 240 240 240 240 240 240 240 240 240 240 240 240 240 240 240 240 240 240 240 240 240 240 240 240 240 240 240 240 240
				240 240 240 240 240 240 240 240 240 240 240 240 240 240 240 240 240 240 240 240 240 240 240 240 240 240 240 240 240 240 240 240
				240 240 240 240 240 240 240 240 240 240 240 240 240 240 240 240 240 240 240 240 240 240 240 240 240 240 240 240 240 240 240 240
				240 240 240 240 240 240 240 240 240 240 240 240 240 240 240 240 240 240 240 240 240 240 240 240 240 240 240 240 240 240 240 240
				240 240 240 240 240 240 240 240 240 240 240 240 240 240 240 240 240 240 240 240 240 240 240 240 240 240 240 240 240 240 240 240
				240 240 240 240 240 240 240 240 240 240 240 240 240 240 240 240 240 240 240 240 240 240 240 240 240 240 240 240 240 240 240 240
				240 240 240 240 240 240 240 240 240 240 240 240 240 240 240 240 240 240 240 240 240 240 240 240 240 240 240 240 240 240 240 240
				240 240 240 240 240 240 240 240 240 240 240 240 240 240 240 240 240 240 240 240 240 240 240 240 240 240 240 240 240 240 240 240
				240 240 240 240 240 240 240 240 240 240 240 240 240 240 240 240 240 240 240 240 240 240 240 240 240 240 240 240 240 240 240 240
				240 240 240 240 240 240 240 240 240 240 240 240 240 240 240 240 240 240 240 240 240 240 240 240 240 240 240 240 240 240 240 240
				240 240 240 240 240 240 240 240 240 240 240 240 240 240 240 240 240 240 240 240 240 240 240 240 240 240 240 240 240 240 240 240
				240 240 240 240 240 240 240 240 240 240 240 240 240 240 240 240 240 240 240 240 240 240 240 240 240 240 240 240 240 240 240 240
				240 240 240 240 240 240 240 240 240 240 240 240 240 240 240 240 240 240 240 240 240 240 240 240 240 240 240 240 240 240 240 240
				240 240 240 240 240 240 240 240 240 240 240 240 240 240 240 240 240 240 240 240 240 240 240 240 240 240 240 240 240 240 240 240
				240 240 240 240 240 240 240 240 240 240 240 240 240 240 240 240 240 240 240 240 240 240 240 240 240 240 240 240 240 240 240 240
				240 240 240 240 240 240 240 240 240 240 240 240 240 240 240 240 240 240 240 240 240 240 240 240 240 240 240 240 240 240 240 240
				240 240 240 240 240 240 240 240 240 240 240 240 240 240 240 240 240 240 240 240 240 240 240 240 240 240 240 240 240 240 240 240
				240 240 240 240 240 240 240 240 240 240 240 240 240 240 240 240 240 240 240 240 240 240 240 240 240 240 240 240 240 240 240 240
				240 240 240 240 240 240 240 240 240 240 240 240 240 240 240 240 240 240 240 240 240 240 240 240 240 240 240 240 240 240 240 240
				240 240 240 240 240 240 240 240 240 240 240 240 240 240 240 240 240 240 240 240 240 240 240 240 240 240 240 240 240 240 240 240
				240 240 240 240 240 240 240 240 240 240 240 240 240 240 240 240 240 240 240 240 240 240 240 240 240 240 240 240 240 240 240 240
				240 240 240 240 240 240 240 240 240 240 240 240 240 240 240 240 240 240 240 240 240 240 240 240 240 240 240 240 240 240 240 240
				240 240 240 240 240 240 240 240 240 240 240 240 240 240 240 240 240 240 240 240 240 240 240 240 240 240 240 240 240 240 240 240
				240 240 240 240 240 240 240 240 240 240 240 240 240 240 240 240 240 240 240 240 240 240 240 240 240 240 240 240 240 240 240 240
				240 240 240 240 240 240 240 240 240 240 240 240 240 240 240 240 240 240 240 240 240 240 240 240 240 240 240 240 240 240 240 240
				240 240 240 240 240 240 240 240 240 240 240 240 240 240 240 240 240 240 240 240 240 240 240 240 240 240 240 240 240 240 240 240
				240 240 240 240 240 240 240 240 240 240 240 240 240 240 240 240 240 240 240 240 240 240 240 240 240 240 240 240 240 240 240 240
				240 240 240 240 240 240 240 240 240 240 240 240 240 240 240 240 240 240 240 240 240 240 240 240 240 240 240 240 240 240 240 240
				240 240 240 240 240 240 240 240 240 240 240 240 240 240 240 240 240 240 240 240 240 240 240 240 240 240 240 240 240 240 240 240
				240 240 240>;

			PS_Config_Lmt_FW_CC_P = <
				314 314 314 314 314 314 314 314 314 314 314 314 314 314 314 314 314 314 314 314 314 314 314 314 314 314 314 314 314 314 314 314
				314 314 314 314 314 314 314 314 314 314 314 314 314 314 314 314 314 314 314 314 314 314 314 314 314 314 314 314 314 314 314 314
				314 314 314 314 314 314 314 314 314 314 314 314 314 314 314 314 314 314 314 314 314 314 314 314 314 314 314 314 314 314 314 314
				314 314 314 314 314 314 314 314 314 314 314 314 314 314 314 314 314 314 314 314 314 314 314 314 314 314 314 314 314 314 314 314
				314 314 314 314 314 314 314 314 314 314 314 314 314 314 314 314 314 314 314 314 314 314 314 314 314 314 314 314 314 314 314 314
				314 314 314 314 314 314 314 314 314 314 314 314 314 314 314 314 314 314 314 314 314 314 314 314 314 314 314 314 314 314 314 314
				314 314 314 314 314 314 314 314 314 314 314 314 314 314 314 314 314 314 314 314 314 314 314 314 314 314 314 314 314 314 314 314
				314 314 314 314 314 314 314 314 314 314 314 314 314 314 314 314 314 314 314 314 314 314 314 314 314 314 314 314 314 314 314 314
				314 314 314 314 314 314 314 314 314 314 314 314 314 314 314 314 314 314 314 314 314 314 314 314 314 314 314 314 314 314 314 314
				314 314 314 314 314 314 314 314 314 314 314 314 314 314 314 314 314 314 314 314 314 314 314 314 314 314 314 314 314 314 314 314
				314 314 314 314 314 314 314 314 314 314 314 314 314 314 314 314 314 314 314 314 314 314 314 314 314 314 314 314 314 314 314 314
				314 314 314 314 314 314 314 314 314 314 314 314 314 314 314 314 314 314 314 314 314 314 314 314 314 314 314 314 314 314 314 314
				314 314 314 314 314 314 314 314 314 314 314 314 314 314 314 314 314 314 314 314 314 314 314 314 314 314 314 314 314 314 314 314
				314 314 314 314 314 314 314 314 314 314 314 314 314 314 314 314 314 314 314 314 314 314 314 314 314 314 314 314 314 314 314 314
				314 314 314 314 314 314 314 314 314 314 314 314 314 314 314 314 314 314 314 314 314 314 314 314 314 314 314 314 314 314 314 314
				314 314 314 314 314 314 314 314 314 314 314 314 314 314 314 314 314 314 314 314 314 314 314 314 314 314 314 314 314 314 314 314
				314 314 314 314 314 314 314 314 314 314 314 314 314 314 314 314 314 314 314 314 314 314 314 314 314 314 314 314 314 314 314 314
				314 314 314 314 314 314 314 314 314 314 314 314 314 314 314 314 314 314 314 314 314 314 314 314 314 314 314 314 314 314 314 314
				314 314 314 314 314 314 314 314 314 314 314 314 314 314 314 314 314 314 314 314 314 314 314 314 314 314 314 314 314 314 314 314
				314 314 314 314 314 314 314 314 314 314 314 314 314 314 314 314 314 314 314 314 314 314 314 314 314 314 314 314 314 314 314 314
				314 314 314 314 314 314 314 314 314 314 314 314 314 314 314 314 314 314 314 314 314 314 314 314 314 314 314 314 314 314 314 314
				314 314 314 314 314 314 314 314 314 314 314 314 314 314 314 314 314 314 314 314 314 314 314 314 314 314 314 314 314 314 314 314
				314 314 314 314 314 314 314 314 314 314 314 314 314 314 314 314 314 314 314 314 314 314 314 314 314 314 314 314 314 314 314 314
				314 314 314 314 314 314 314 314 314 314 314 314 314 314 314 314 314 314 314 314 314 314 314 314 314 314 314 314 314 314 314 314
				314 314 314 314 314 314 314 314 314 314 314 314 314 314 314 314 314 314 314 314 314 314 314 314 314 314 314 314 314 314 314 314
				314 314 314 314 314 314 314 314 314 314 314 314 314 314 314 314 314 314 314 314 314 314 314 314 314 314 314 314 314 314 314 314
				314 314 314 314 314 314 314 314 314 314 314 314 314 314 314 314 314 314 314 314 314 314 314 314 314 314 314 314 314 314 314 314
				314 314 314 314 314 314 314 314 314 314 314 314 314 314 314 314 314 314 314 314 314 314 314 314 314 314 314 314 314 314 314 314
				314 314 314 314 314 314 314 314 314 314 314 314 314 314 314 314 314 314 314 314 314 314 314 314 314 314 314 314 314 314 314 314
				314 314 314 314 314 314 314 314 314 314 314 314 314 314 314 314 314 314 314 314 314 314 314 314 314 314 314 314 314 314 314 314
				314 314 314 314 314 314 314 314 314 314 314 314 314 314 314 314 314 314 314 314 314 314 314 314 314 314 314 314 314 314 314 314
				314 314 314 314 314 314 314 314 314 314 314 314 314 314 314 314 314 314 314 314 314 314 314 314 314 314 314 314 314 314 314 314
				314 314 314 314 314 314 314 314 314 314 314 314 314 314 314 314 314 314 314 314 314 314 314 314 314 314 314 314 314 314 314 314
				314 314 314 314 314 314 314 314 314 314 314 314 314 314 314 314 314 314 314 314 314 314 314 314 314 314 314 314 314 314 314 314
				314 314 314 314 314 314 314 314 314 314 314 314 314 314 314 314 314 314 314 314 314 314 314 314 314 314 314 314 314 314 314 314
				314 314 314 314 314 314 314 314 314 314 314 314 314 314 314 314 314 314 314 314 314 314 314 314 314 314 314 314 314 314 314 314
				314 314 314 314 314 314 314 314 314 314 314 314 314 314 314 314 314 314 314 314 314 314 314 314 314 314 314 314 314 314 314 314
				314 314 314 314 314 314 314 314 314 314 314 314 314 314 314 314 314 314 314 314 314 314 314 314 314 314 314 314 314 314 314 314
				314 314 314 314 314 314 314 314 314 314 314 314 314 314 314 314 314 314 314 314 314 314 314 314 314 314 314 314 314 314 314 314
				314 314 314 314 314 314 314 314 314 314 314 314 314 314 314 314 314 314 314 314 314 314 314 314 314 314 314 314 314 314 314 314
				314 314 314 314 314 314 314 314 314 314 314 314 314 314 314 314 314 314 314 314 314 314 314 314 314 314 314 314 314 314 314 314
				314 314 314 314 314 314 314 314 314 314 314 314 314 314 314 314 314 314 314 314 314 314 314 314 314 314 314 314 314 314 314 314
				314 314 314 314 314 314 314 314 314 314 314 314 314 314 314 314 314 314 314 314 314 314 314 314 314 314 314 314 314 314 314 314
				314 314 314 314 314 314 314 314 314 314 314 314 314 314 314 314 314 314 314 314 314 314 314 314 314 314 314 314 314 314 314 314
				314 314 314 314 314 314 314 314 314 314 314 314 314 314 314 314 314 314 314 314 314 314 314 314 314 314 314 314 314 314 314 314
				314 314 314 314 314 314 314 314 314 314 314 314 314 314 314 314 314 314 314 314 314 314 314 314 314 314 314 314 314 314 314 314
				314 314 314 314 314 314 314 314 314 314 314 314 314 314 314 314 314 314 314 314 314 314 314 314 314 314 314 314 314 314 314 314
				314 314 314 314 314 314 314 314 314 314 314 314 314 314 314 314 314 314 314 314 314 314 314 314 314 314 314 314 314 314 314 314
				314 314 314>;

			PS_Config_Lmt_FW_CC_N = <
				0 0 0 0 0 0 0 0 0 0 0 0 0 0 0 0 0 0 0 0 0 0 0 0 0 0 0 0 0 0 0 0
				0 0 0 0 0 0 0 0 0 0 0 0 0 0 0 0 0 0 0 0 0 0 0 0 0 0 0 0 0 0 0 0
				0 0 0 0 0 0 0 0 0 0 0 0 0 0 0 0 0 0 0 0 0 0 0 0 0 0 0 0 0 0 0 0
				0 0 0 0 0 0 0 0 0 0 0 0 0 0 0 0 0 0 0 0 0 0 0 0 0 0 0 0 0 0 0 0
				0 0 0 0 0 0 0 0 0 0 0 0 0 0 0 0 0 0 0 0 0 0 0 0 0 0 0 0 0 0 0 0
				0 0 0 0 0 0 0 0 0 0 0 0 0 0 0 0 0 0 0 0 0 0 0 0 0 0 0 0 0 0 0 0
				0 0 0 0 0 0 0 0 0 0 0 0 0 0 0 0 0 0 0 0 0 0 0 0 0 0 0 0 0 0 0 0
				0 0 0 0 0 0 0 0 0 0 0 0 0 0 0 0 0 0 0 0 0 0 0 0 0 0 0 0 0 0 0 0
				0 0 0 0 0 0 0 0 0 0 0 0 0 0 0 0 0 0 0 0 0 0 0 0 0 0 0 0 0 0 0 0
				0 0 0 0 0 0 0 0 0 0 0 0 0 0 0 0 0 0 0 0 0 0 0 0 0 0 0 0 0 0 0 0
				0 0 0 0 0 0 0 0 0 0 0 0 0 0 0 0 0 0 0 0 0 0 0 0 0 0 0 0 0 0 0 0
				0 0 0 0 0 0 0 0 0 0 0 0 0 0 0 0 0 0 0 0 0 0 0 0 0 0 0 0 0 0 0 0
				0 0 0 0 0 0 0 0 0 0 0 0 0 0 0 0 0 0 0 0 0 0 0 0 0 0 0 0 0 0 0 0
				0 0 0 0 0 0 0 0 0 0 0 0 0 0 0 0 0 0 0 0 0 0 0 0 0 0 0 0 0 0 0 0
				0 0 0 0 0 0 0 0 0 0 0 0 0 0 0 0 0 0 0 0 0 0 0 0 0 0 0 0 0 0 0 0
				0 0 0 0 0 0 0 0 0 0 0 0 0 0 0 0 0 0 0 0 0 0 0 0 0 0 0 0 0 0 0 0
				0 0 0 0 0 0 0 0 0 0 0 0 0 0 0 0 0 0 0 0 0 0 0 0 0 0 0 0 0 0 0 0
				0 0 0 0 0 0 0 0 0 0 0 0 0 0 0 0 0 0 0 0 0 0 0 0 0 0 0 0 0 0 0 0
				0 0 0 0 0 0 0 0 0 0 0 0 0 0 0 0 0 0 0 0 0 0 0 0 0 0 0 0 0 0 0 0
				0 0 0 0 0 0 0 0 0 0 0 0 0 0 0 0 0 0 0 0 0 0 0 0 0 0 0 0 0 0 0 0
				0 0 0 0 0 0 0 0 0 0 0 0 0 0 0 0 0 0 0 0 0 0 0 0 0 0 0 0 0 0 0 0
				0 0 0 0 0 0 0 0 0 0 0 0 0 0 0 0 0 0 0 0 0 0 0 0 0 0 0 0 0 0 0 0
				0 0 0 0 0 0 0 0 0 0 0 0 0 0 0 0 0 0 0 0 0 0 0 0 0 0 0 0 0 0 0 0
				0 0 0 0 0 0 0 0 0 0 0 0 0 0 0 0 0 0 0 0 0 0 0 0 0 0 0 0 0 0 0 0
				0 0 0 0 0 0 0 0 0 0 0 0 0 0 0 0 0 0 0 0 0 0 0 0 0 0 0 0 0 0 0 0
				0 0 0 0 0 0 0 0 0 0 0 0 0 0 0 0 0 0 0 0 0 0 0 0 0 0 0 0 0 0 0 0
				0 0 0 0 0 0 0 0 0 0 0 0 0 0 0 0 0 0 0 0 0 0 0 0 0 0 0 0 0 0 0 0
				0 0 0 0 0 0 0 0 0 0 0 0 0 0 0 0 0 0 0 0 0 0 0 0 0 0 0 0 0 0 0 0
				0 0 0 0 0 0 0 0 0 0 0 0 0 0 0 0 0 0 0 0 0 0 0 0 0 0 0 0 0 0 0 0
				0 0 0 0 0 0 0 0 0 0 0 0 0 0 0 0 0 0 0 0 0 0 0 0 0 0 0 0 0 0 0 0
				0 0 0 0 0 0 0 0 0 0 0 0 0 0 0 0 0 0 0 0 0 0 0 0 0 0 0 0 0 0 0 0
				0 0 0 0 0 0 0 0 0 0 0 0 0 0 0 0 0 0 0 0 0 0 0 0 0 0 0 0 0 0 0 0
				0 0 0 0 0 0 0 0 0 0 0 0 0 0 0 0 0 0 0 0 0 0 0 0 0 0 0 0 0 0 0 0
				0 0 0 0 0 0 0 0 0 0 0 0 0 0 0 0 0 0 0 0 0 0 0 0 0 0 0 0 0 0 0 0
				0 0 0 0 0 0 0 0 0 0 0 0 0 0 0 0 0 0 0 0 0 0 0 0 0 0 0 0 0 0 0 0
				0 0 0 0 0 0 0 0 0 0 0 0 0 0 0 0 0 0 0 0 0 0 0 0 0 0 0 0 0 0 0 0
				0 0 0 0 0 0 0 0 0 0 0 0 0 0 0 0 0 0 0 0 0 0 0 0 0 0 0 0 0 0 0 0
				0 0 0 0 0 0 0 0 0 0 0 0 0 0 0 0 0 0 0 0 0 0 0 0 0 0 0 0 0 0 0 0
				0 0 0 0 0 0 0 0 0 0 0 0 0 0 0 0 0 0 0 0 0 0 0 0 0 0 0 0 0 0 0 0
				0 0 0 0 0 0 0 0 0 0 0 0 0 0 0 0 0 0 0 0 0 0 0 0 0 0 0 0 0 0 0 0
				0 0 0 0 0 0 0 0 0 0 0 0 0 0 0 0 0 0 0 0 0 0 0 0 0 0 0 0 0 0 0 0
				0 0 0 0 0 0 0 0 0 0 0 0 0 0 0 0 0 0 0 0 0 0 0 0 0 0 0 0 0 0 0 0
				0 0 0 0 0 0 0 0 0 0 0 0 0 0 0 0 0 0 0 0 0 0 0 0 0 0 0 0 0 0 0 0
				0 0 0 0 0 0 0 0 0 0 0 0 0 0 0 0 0 0 0 0 0 0 0 0 0 0 0 0 0 0 0 0
				0 0 0 0 0 0 0 0 0 0 0 0 0 0 0 0 0 0 0 0 0 0 0 0 0 0 0 0 0 0 0 0
				0 0 0 0 0 0 0 0 0 0 0 0 0 0 0 0 0 0 0 0 0 0 0 0 0 0 0 0 0 0 0 0
				0 0 0 0 0 0 0 0 0 0 0 0 0 0 0 0 0 0 0 0 0 0 0 0 0 0 0 0 0 0 0 0
				0 0 0 0 0 0 0 0 0 0 0 0 0 0 0 0 0 0 0 0 0 0 0 0 0 0 0 0 0 0 0 0
				0 0 0>;

			PS_Config_Lmt_FW_Diff_P = <
				75 75 75 75 75 75 75 75 75 75 75 75 75 75 75 75 75 75 75 75 75 75 75 75 75 75 75 75 75 75 75 75
				75 75 75 75 75 75 75 75 75 75 75 75 75 75 75 75 75 75 75 75 75 75 75 75 75 75 75 75 75 75 75 75
				75 75 75 75 75 75 75 75 75 75 75 75 75 75 75 75 75 75 75 75 75 75 75 75 75 75 75 75 75 75 75 75
				75 75 75 75 75 75 75 75 75 75 75 75 75 75 75 75 75 75 75 75 75 75 75 75 75 75 75 75 75 75 75 75
				75 75 75 75 75 75 75 75 75 75 75 75 75 75 75 75 75 75 75 75 75 75 75 75 75 75 75 75 75 75 75 75
				75 75 75 75 75 75 75 75 75 75 75 75 75 75 75 75 75 75 75 75 75 75 75 75 75 75 75 75 75 75 75 75
				75 75 75 75 75 75 75 75 75 75 75 75 75 75 75 75 75 75 75 75 75 75 75 75 75 75 75 75 75 75 75 75
				75 75 75 75 75 75 75 75 75 75 75 75 75 75 75 75 75 75 75 75 75 75 75 75 75 75 75 75 75 75 75 75
				75 75 75 75 75 75 75 75 75 75 75 75 75 75 75 75 75 75 75 75 75 75 75 75 75 75 75 75 75 75 75 75
				75 75 75 75 75 75 75 75 75 75 75 75 75 75 75 75 75 75 75 75 75 75 75 75 75 75 75 75 75 75 75 75
				75 75 75 75 75 75 75 75 75 75 75 75 75 75 75 75 75 75 75 75 75 75 75 75 75 75 75 75 75 75 75 75
				75 75 75 75 75 75 75 75 75 75 75 75 75 75 75 75 75 75 75 75 75 75 75 75 75 75 75 75 75 75 75 75
				75 75 75 75 75 75 75 75 75 75 75 75 75 75 75 75 75 75 75 75 75 75 75 75 75 75 75 75 75 75 75 75
				75 75 75 75 75 75 75 75 75 75 75 75 75 75 75 75 75 75 75 75 75 75 75 75 75 75 75 75 75 75 75 75
				75 75 75 75 75 75 75 75 75 75 75 75 75 75 75 75 75 75 75 75 75 75 75 75 75 75 75 75 75 75 75 75
				75 75 75 75 75 75 75 75 75 75 75 75 75 75 75 75 75 75 75 75 75 75 75 75 75 75 75 75 75 75 75 75
				75 75 75 75 75 75 75 75 75 75 75 75 75 75 75 75 75 75 75 75 75 75 75 75 75 75 75 75 75 75 75 75
				75 75 75 75 75 75 75 75 75 75 75 75 75 75 75 75 75 75 75 75 75 75 75 75 75 75 75 75 75 75 75 75
				75 75 75 75 75 75 75 75 75 75 75 75 75 75 75 75 75 75 75 75 75 75 75 75 75 75 75 75 75 75 75 75
				75 75 75 75 75 75 75 75 75 75 75 75 75 75 75 75 75 75 75 75 75 75 75 75 75 75 75 75 75 75 75 75
				75 75 75 75 75 75 75 75 75 75 75 75 75 75 75 75 75 75 75 75 75 75 75 75 75 75 75 75 75 75 75 75
				75 75 75 75 75 75 75 75 75 75 75 75 75 75 75 75 75 75 75 75 75 75 75 75 75 75 75 75 75 75 75 75
				75 75 75 75 75 75 75 75 75 75 75 75 75 75 75 75 75 75 75 75 75 75 75 75 75 75 75 75 75 75 75 75
				75 75 75 75 75 75 75 75 75 75 75 75 75 75 75 75 75 75 75 75 75 75 75 75 75 75 75 75 75 75 75 75
				75 75 75 75 75 75 75 75 75 75 75 75 75 75 75 75 75 75 75 75 75 75 75 75 75 75 75 75 75 75 75 75
				75 75 75 75 75 75 75 75 75 75 75 75 75 75 75 75 75 75 75 75 75 75 75 75 75 75 75 75 75 75 75 75
				75 75 75 75 75 75 75 75 75 75 75 75 75 75 75 75 75 75 75 75 75 75 75 75 75 75 75 75 75 75 75 75
				75 75 75 75 75 75 75 75 75 75 75 75 75 75 75 75 75 75 75 75 75 75 75 75 75 75 75 75 75 75 75 75
				75 75 75 75 75 75 75 75 75 75 75 75 75 75 75 75 75 75 75 75 75 75 75 75 75 75 75 75 75 75 75 75
				75 75 75 75 75 75 75 75 75 75 75 75 75 75 75 75 75 75 75 75 75 75 75 75 75 75 75 75 75 75 75 75
				75 75 75 75 75 75 75 75 75 75 75 75 75 75 75 75 75 75 75 75 75 75 75 75 75 75 75 75 75 75 75 75
				75 75 75 75 75 75 75 75 75 75 75 75 75 75 75 75 75 75 75 75 75 75 75 75 75 75 75 75 75 75 75 75
				75 75 75 75 75 75 75 75 75 75 75 75 75 75 75 75 75 75 75 75 75 75 75 75 75 75 75 75 75 75 75 75
				75 75 75 75 75 75 75 75 75 75 75 75 75 75 75 75 75 75 75 75 75 75 75 75 75 75 75 75 75 75 75 75
				75 75 75 75 75 75 75 75 75 75 75 75 75 75 75 75 75 75 75 75 75 75 75 75 75 75 75 75 75 75 75 75
				75 75 75 75 75 75 75 75 75 75 75 75 75 75 75 75 75 75 75 75 75 75 75 75 75 75 75 75 75 75 75 75
				75 75 75 75 75 75 75 75 75 75 75 75 75 75 75 75 75 75 75 75 75 75 75 75 75 75 75 75 75 75 75 75
				75 75 75 75 75 75 75 75 75 75 75 75 75 75 75 75 75 75 75 75 75 75 75 75 75 75 75 75 75 75 75 75
				75 75 75 75 75 75 75 75 75 75 75 75 75 75 75 75 75 75 75 75 75 75 75 75 75 75 75 75 75 75 75 75
				75 75 75 75 75 75 75 75 75 75 75 75 75 75 75 75 75 75 75 75 75 75 75 75 75 75 75 75 75 75 75 75
				75 75 75 75 75 75 75 75 75 75 75 75 75 75 75 75 75 75 75 75 75 75 75 75 75 75 75 75 75 75 75 75
				75 75 75 75 75 75 75 75 75 75 75 75 75 75 75 75 75 75 75 75 75 75 75 75 75 75 75 75 75 75 75 75
				75 75 75 75 75 75 75 75 75 75 75 75 75 75 75 75 75 75 75 75 75 75 75 75 75 75 75 75 75 75 75 75
				75 75 75 75 75 75 75 75 75 75 75 75 75 75 75 75 75 75 75 75 75 75 75 75 75 75 75 75 75 75 75 75
				75 75 75 75 75 75 75 75 75 75 75 75 75 75 75 75 75 75 75 75 75 75 75 75 75 75 75 75 75 75 75 75
				75 75 75 75 75 75 75 75 75 75 75 75 75 75 75 75 75 75 75 75 75 75 75 75 75 75 75 75 75 75 75 75
				75 75 75 75 75 75 75 75 75 75 75 75 75 75 75 75 75 75 75 75 75 75 75 75 75 75 75 75 75 75 75 75
				75 75 75 75 75 75 75 75 75 75 75 75 75 75 75 75 75 75 75 75 75 75 75 75 75 75 75 75 75 75 75 75
				75 75 75>;

			PS_Config_Lmt_FW_Diff_N = <
				(-75) (-75) (-75) (-75) (-75) (-75) (-75) (-75) (-75) (-75) (-75) (-75) (-75) (-75) (-75) (-75) (-75) (-75) (-75) (-75) (-75) (-75) (-75) (-75) (-75) (-75) (-75) (-75) (-75) (-75) (-75) (-75)
				(-75) (-75) (-75) (-75) (-75) (-75) (-75) (-75) (-75) (-75) (-75) (-75) (-75) (-75) (-75) (-75) (-75) (-75) (-75) (-75) (-75) (-75) (-75) (-75) (-75) (-75) (-75) (-75) (-75) (-75) (-75) (-75)
				(-75) (-75) (-75) (-75) (-75) (-75) (-75) (-75) (-75) (-75) (-75) (-75) (-75) (-75) (-75) (-75) (-75) (-75) (-75) (-75) (-75) (-75) (-75) (-75) (-75) (-75) (-75) (-75) (-75) (-75) (-75) (-75)
				(-75) (-75) (-75) (-75) (-75) (-75) (-75) (-75) (-75) (-75) (-75) (-75) (-75) (-75) (-75) (-75) (-75) (-75) (-75) (-75) (-75) (-75) (-75) (-75) (-75) (-75) (-75) (-75) (-75) (-75) (-75) (-75)
				(-75) (-75) (-75) (-75) (-75) (-75) (-75) (-75) (-75) (-75) (-75) (-75) (-75) (-75) (-75) (-75) (-75) (-75) (-75) (-75) (-75) (-75) (-75) (-75) (-75) (-75) (-75) (-75) (-75) (-75) (-75) (-75)
				(-75) (-75) (-75) (-75) (-75) (-75) (-75) (-75) (-75) (-75) (-75) (-75) (-75) (-75) (-75) (-75) (-75) (-75) (-75) (-75) (-75) (-75) (-75) (-75) (-75) (-75) (-75) (-75) (-75) (-75) (-75) (-75)
				(-75) (-75) (-75) (-75) (-75) (-75) (-75) (-75) (-75) (-75) (-75) (-75) (-75) (-75) (-75) (-75) (-75) (-75) (-75) (-75) (-75) (-75) (-75) (-75) (-75) (-75) (-75) (-75) (-75) (-75) (-75) (-75)
				(-75) (-75) (-75) (-75) (-75) (-75) (-75) (-75) (-75) (-75) (-75) (-75) (-75) (-75) (-75) (-75) (-75) (-75) (-75) (-75) (-75) (-75) (-75) (-75) (-75) (-75) (-75) (-75) (-75) (-75) (-75) (-75)
				(-75) (-75) (-75) (-75) (-75) (-75) (-75) (-75) (-75) (-75) (-75) (-75) (-75) (-75) (-75) (-75) (-75) (-75) (-75) (-75) (-75) (-75) (-75) (-75) (-75) (-75) (-75) (-75) (-75) (-75) (-75) (-75)
				(-75) (-75) (-75) (-75) (-75) (-75) (-75) (-75) (-75) (-75) (-75) (-75) (-75) (-75) (-75) (-75) (-75) (-75) (-75) (-75) (-75) (-75) (-75) (-75) (-75) (-75) (-75) (-75) (-75) (-75) (-75) (-75)
				(-75) (-75) (-75) (-75) (-75) (-75) (-75) (-75) (-75) (-75) (-75) (-75) (-75) (-75) (-75) (-75) (-75) (-75) (-75) (-75) (-75) (-75) (-75) (-75) (-75) (-75) (-75) (-75) (-75) (-75) (-75) (-75)
				(-75) (-75) (-75) (-75) (-75) (-75) (-75) (-75) (-75) (-75) (-75) (-75) (-75) (-75) (-75) (-75) (-75) (-75) (-75) (-75) (-75) (-75) (-75) (-75) (-75) (-75) (-75) (-75) (-75) (-75) (-75) (-75)
				(-75) (-75) (-75) (-75) (-75) (-75) (-75) (-75) (-75) (-75) (-75) (-75) (-75) (-75) (-75) (-75) (-75) (-75) (-75) (-75) (-75) (-75) (-75) (-75) (-75) (-75) (-75) (-75) (-75) (-75) (-75) (-75)
				(-75) (-75) (-75) (-75) (-75) (-75) (-75) (-75) (-75) (-75) (-75) (-75) (-75) (-75) (-75) (-75) (-75) (-75) (-75) (-75) (-75) (-75) (-75) (-75) (-75) (-75) (-75) (-75) (-75) (-75) (-75) (-75)
				(-75) (-75) (-75) (-75) (-75) (-75) (-75) (-75) (-75) (-75) (-75) (-75) (-75) (-75) (-75) (-75) (-75) (-75) (-75) (-75) (-75) (-75) (-75) (-75) (-75) (-75) (-75) (-75) (-75) (-75) (-75) (-75)
				(-75) (-75) (-75) (-75) (-75) (-75) (-75) (-75) (-75) (-75) (-75) (-75) (-75) (-75) (-75) (-75) (-75) (-75) (-75) (-75) (-75) (-75) (-75) (-75) (-75) (-75) (-75) (-75) (-75) (-75) (-75) (-75)
				(-75) (-75) (-75) (-75) (-75) (-75) (-75) (-75) (-75) (-75) (-75) (-75) (-75) (-75) (-75) (-75) (-75) (-75) (-75) (-75) (-75) (-75) (-75) (-75) (-75) (-75) (-75) (-75) (-75) (-75) (-75) (-75)
				(-75) (-75) (-75) (-75) (-75) (-75) (-75) (-75) (-75) (-75) (-75) (-75) (-75) (-75) (-75) (-75) (-75) (-75) (-75) (-75) (-75) (-75) (-75) (-75) (-75) (-75) (-75) (-75) (-75) (-75) (-75) (-75)
				(-75) (-75) (-75) (-75) (-75) (-75) (-75) (-75) (-75) (-75) (-75) (-75) (-75) (-75) (-75) (-75) (-75) (-75) (-75) (-75) (-75) (-75) (-75) (-75) (-75) (-75) (-75) (-75) (-75) (-75) (-75) (-75)
				(-75) (-75) (-75) (-75) (-75) (-75) (-75) (-75) (-75) (-75) (-75) (-75) (-75) (-75) (-75) (-75) (-75) (-75) (-75) (-75) (-75) (-75) (-75) (-75) (-75) (-75) (-75) (-75) (-75) (-75) (-75) (-75)
				(-75) (-75) (-75) (-75) (-75) (-75) (-75) (-75) (-75) (-75) (-75) (-75) (-75) (-75) (-75) (-75) (-75) (-75) (-75) (-75) (-75) (-75) (-75) (-75) (-75) (-75) (-75) (-75) (-75) (-75) (-75) (-75)
				(-75) (-75) (-75) (-75) (-75) (-75) (-75) (-75) (-75) (-75) (-75) (-75) (-75) (-75) (-75) (-75) (-75) (-75) (-75) (-75) (-75) (-75) (-75) (-75) (-75) (-75) (-75) (-75) (-75) (-75) (-75) (-75)
				(-75) (-75) (-75) (-75) (-75) (-75) (-75) (-75) (-75) (-75) (-75) (-75) (-75) (-75) (-75) (-75) (-75) (-75) (-75) (-75) (-75) (-75) (-75) (-75) (-75) (-75) (-75) (-75) (-75) (-75) (-75) (-75)
				(-75) (-75) (-75) (-75) (-75) (-75) (-75) (-75) (-75) (-75) (-75) (-75) (-75) (-75) (-75) (-75) (-75) (-75) (-75) (-75) (-75) (-75) (-75) (-75) (-75) (-75) (-75) (-75) (-75) (-75) (-75) (-75)
				(-75) (-75) (-75) (-75) (-75) (-75) (-75) (-75) (-75) (-75) (-75) (-75) (-75) (-75) (-75) (-75) (-75) (-75) (-75) (-75) (-75) (-75) (-75) (-75) (-75) (-75) (-75) (-75) (-75) (-75) (-75) (-75)
				(-75) (-75) (-75) (-75) (-75) (-75) (-75) (-75) (-75) (-75) (-75) (-75) (-75) (-75) (-75) (-75) (-75) (-75) (-75) (-75) (-75) (-75) (-75) (-75) (-75) (-75) (-75) (-75) (-75) (-75) (-75) (-75)
				(-75) (-75) (-75) (-75) (-75) (-75) (-75) (-75) (-75) (-75) (-75) (-75) (-75) (-75) (-75) (-75) (-75) (-75) (-75) (-75) (-75) (-75) (-75) (-75) (-75) (-75) (-75) (-75) (-75) (-75) (-75) (-75)
				(-75) (-75) (-75) (-75) (-75) (-75) (-75) (-75) (-75) (-75) (-75) (-75) (-75) (-75) (-75) (-75) (-75) (-75) (-75) (-75) (-75) (-75) (-75) (-75) (-75) (-75) (-75) (-75) (-75) (-75) (-75) (-75)
				(-75) (-75) (-75) (-75) (-75) (-75) (-75) (-75) (-75) (-75) (-75) (-75) (-75) (-75) (-75) (-75) (-75) (-75) (-75) (-75) (-75) (-75) (-75) (-75) (-75) (-75) (-75) (-75) (-75) (-75) (-75) (-75)
				(-75) (-75) (-75) (-75) (-75) (-75) (-75) (-75) (-75) (-75) (-75) (-75) (-75) (-75) (-75) (-75) (-75) (-75) (-75) (-75) (-75) (-75) (-75) (-75) (-75) (-75) (-75) (-75) (-75) (-75) (-75) (-75)
				(-75) (-75) (-75) (-75) (-75) (-75) (-75) (-75) (-75) (-75) (-75) (-75) (-75) (-75) (-75) (-75) (-75) (-75) (-75) (-75) (-75) (-75) (-75) (-75) (-75) (-75) (-75) (-75) (-75) (-75) (-75) (-75)
				(-75) (-75) (-75) (-75) (-75) (-75) (-75) (-75) (-75) (-75) (-75) (-75) (-75) (-75) (-75) (-75) (-75) (-75) (-75) (-75) (-75) (-75) (-75) (-75) (-75) (-75) (-75) (-75) (-75) (-75) (-75) (-75)
				(-75) (-75) (-75) (-75) (-75) (-75) (-75) (-75) (-75) (-75) (-75) (-75) (-75) (-75) (-75) (-75) (-75) (-75) (-75) (-75) (-75) (-75) (-75) (-75) (-75) (-75) (-75) (-75) (-75) (-75) (-75) (-75)
				(-75) (-75) (-75) (-75) (-75) (-75) (-75) (-75) (-75) (-75) (-75) (-75) (-75) (-75) (-75) (-75) (-75) (-75) (-75) (-75) (-75) (-75) (-75) (-75) (-75) (-75) (-75) (-75) (-75) (-75) (-75) (-75)
				(-75) (-75) (-75) (-75) (-75) (-75) (-75) (-75) (-75) (-75) (-75) (-75) (-75) (-75) (-75) (-75) (-75) (-75) (-75) (-75) (-75) (-75) (-75) (-75) (-75) (-75) (-75) (-75) (-75) (-75) (-75) (-75)
				(-75) (-75) (-75) (-75) (-75) (-75) (-75) (-75) (-75) (-75) (-75) (-75) (-75) (-75) (-75) (-75) (-75) (-75) (-75) (-75) (-75) (-75) (-75) (-75) (-75) (-75) (-75) (-75) (-75) (-75) (-75) (-75)
				(-75) (-75) (-75) (-75) (-75) (-75) (-75) (-75) (-75) (-75) (-75) (-75) (-75) (-75) (-75) (-75) (-75) (-75) (-75) (-75) (-75) (-75) (-75) (-75) (-75) (-75) (-75) (-75) (-75) (-75) (-75) (-75)
				(-75) (-75) (-75) (-75) (-75) (-75) (-75) (-75) (-75) (-75) (-75) (-75) (-75) (-75) (-75) (-75) (-75) (-75) (-75) (-75) (-75) (-75) (-75) (-75) (-75) (-75) (-75) (-75) (-75) (-75) (-75) (-75)
				(-75) (-75) (-75) (-75) (-75) (-75) (-75) (-75) (-75) (-75) (-75) (-75) (-75) (-75) (-75) (-75) (-75) (-75) (-75) (-75) (-75) (-75) (-75) (-75) (-75) (-75) (-75) (-75) (-75) (-75) (-75) (-75)
				(-75) (-75) (-75) (-75) (-75) (-75) (-75) (-75) (-75) (-75) (-75) (-75) (-75) (-75) (-75) (-75) (-75) (-75) (-75) (-75) (-75) (-75) (-75) (-75) (-75) (-75) (-75) (-75) (-75) (-75) (-75) (-75)
				(-75) (-75) (-75) (-75) (-75) (-75) (-75) (-75) (-75) (-75) (-75) (-75) (-75) (-75) (-75) (-75) (-75) (-75) (-75) (-75) (-75) (-75) (-75) (-75) (-75) (-75) (-75) (-75) (-75) (-75) (-75) (-75)
				(-75) (-75) (-75) (-75) (-75) (-75) (-75) (-75) (-75) (-75) (-75) (-75) (-75) (-75) (-75) (-75) (-75) (-75) (-75) (-75) (-75) (-75) (-75) (-75) (-75) (-75) (-75) (-75) (-75) (-75) (-75) (-75)
				(-75) (-75) (-75) (-75) (-75) (-75) (-75) (-75) (-75) (-75) (-75) (-75) (-75) (-75) (-75) (-75) (-75) (-75) (-75) (-75) (-75) (-75) (-75) (-75) (-75) (-75) (-75) (-75) (-75) (-75) (-75) (-75)
				(-75) (-75) (-75) (-75) (-75) (-75) (-75) (-75) (-75) (-75) (-75) (-75) (-75) (-75) (-75) (-75) (-75) (-75) (-75) (-75) (-75) (-75) (-75) (-75) (-75) (-75) (-75) (-75) (-75) (-75) (-75) (-75)
				(-75) (-75) (-75) (-75) (-75) (-75) (-75) (-75) (-75) (-75) (-75) (-75) (-75) (-75) (-75) (-75) (-75) (-75) (-75) (-75) (-75) (-75) (-75) (-75) (-75) (-75) (-75) (-75) (-75) (-75) (-75) (-75)
				(-75) (-75) (-75) (-75) (-75) (-75) (-75) (-75) (-75) (-75) (-75) (-75) (-75) (-75) (-75) (-75) (-75) (-75) (-75) (-75) (-75) (-75) (-75) (-75) (-75) (-75) (-75) (-75) (-75) (-75) (-75) (-75)
				(-75) (-75) (-75) (-75) (-75) (-75) (-75) (-75) (-75) (-75) (-75) (-75) (-75) (-75) (-75) (-75) (-75) (-75) (-75) (-75) (-75) (-75) (-75) (-75) (-75) (-75) (-75) (-75) (-75) (-75) (-75) (-75)
				(-75) (-75) (-75) (-75) (-75) (-75) (-75) (-75) (-75) (-75) (-75) (-75) (-75) (-75) (-75) (-75) (-75) (-75) (-75) (-75) (-75) (-75) (-75) (-75) (-75) (-75) (-75) (-75) (-75) (-75) (-75) (-75)
				(-75) (-75) (-75)>;

			PS_Config_Diff_Test_Frame = <50>;
		};
	};
};

&pio{
/*
	spi_pins_0:spi0@1{
		pins_cmd_dat{
			pinmux = <PINMUX_GPIO30__FUNC_SPI0_CLK>,
					 <PINMUX_GPIO32__FUNC_SPI0_MO>,
					 <PINMUX_GPIO33__FUNC_SPI0_MI>;
			drive-strength = <2>;
		};
	};
*/

    spi_pull_down_ctrl: spi_pull_down_ctrl {
        pins_cmd_dat {
            pinmux = <PINMUX_GPIO31__FUNC_GPIO31>;
            output-low;
        };
    };

    spi_pull_up_ctrl: spi_pull_up_ctrl {
        pins_cmd_dat {
            pinmux = <PINMUX_GPIO31__FUNC_SPI0_CSB>;
            drive-strength = <2>;
        };
    };
};
